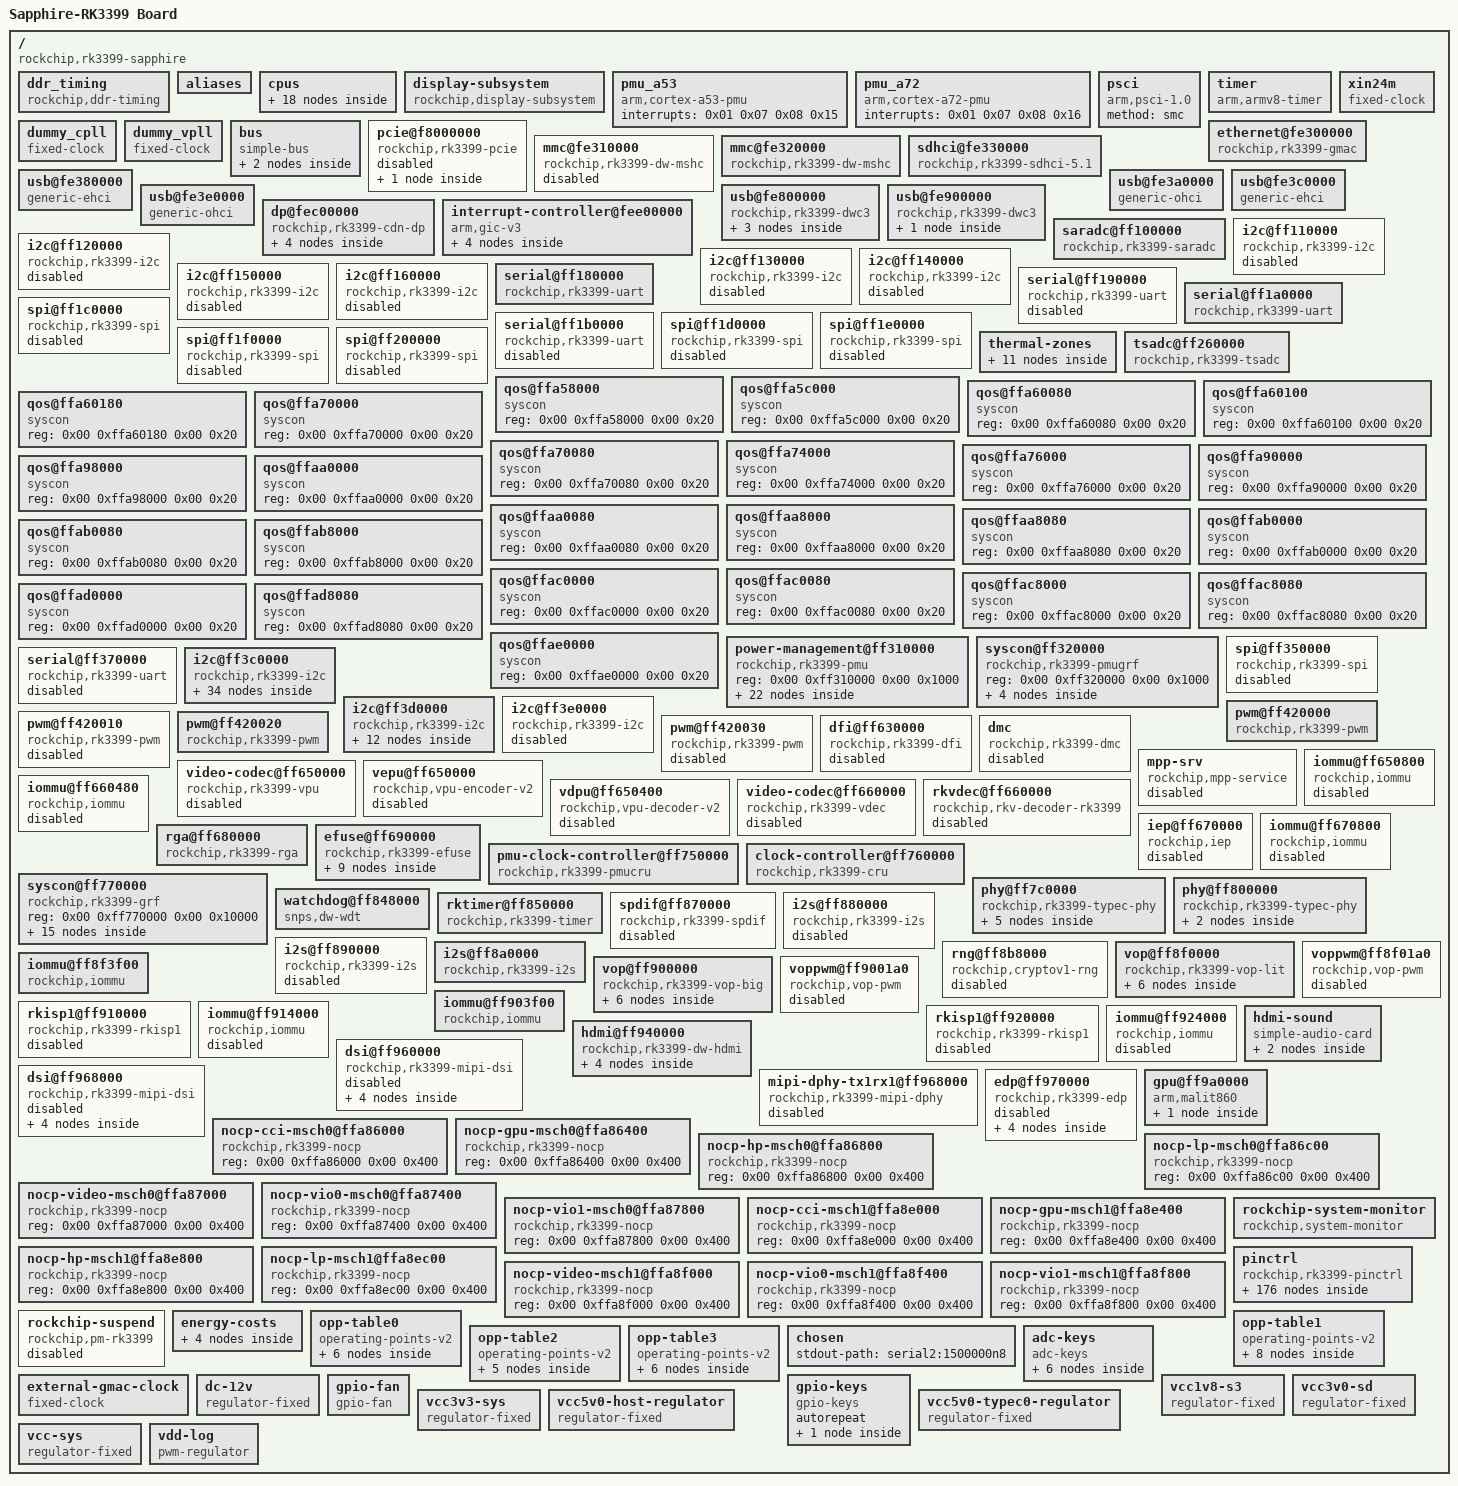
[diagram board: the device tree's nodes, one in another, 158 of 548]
/dts-v1/;

/ {
	compatible = "rockchip,rk3399-sapphire\0rockchip,rk3399";
	interrupt-parent = <0x01>;
	#address-cells = <0x02>;
	#size-cells = <0x02>;
	model = "Sapphire-RK3399 Board";

	ddr_timing {
		compatible = "rockchip,ddr-timing";
		ddr3_speed_bin = <0x15>;
		pd_idle = <0x00>;
		sr_idle = <0x00>;
		sr_mc_gate_idle = <0x00>;
		srpd_lite_idle = <0x00>;
		standby_idle = <0x00>;
		auto_lp_dis_freq = <0x29a>;
		ddr3_dll_dis_freq = <0x12c>;
		phy_dll_dis_freq = <0x104>;
		ddr3_odt_dis_freq = <0x29a>;
		ddr3_drv = <0x28>;
		ddr3_odt = <0x78>;
		phy_ddr3_ca_drv = <0x28>;
		phy_ddr3_dq_drv = <0x28>;
		phy_ddr3_odt = <0xf0>;
		lpddr3_odt_dis_freq = <0x29a>;
		lpddr3_drv = <0x22>;
		lpddr3_odt = <0xf0>;
		phy_lpddr3_ca_drv = <0x22>;
		phy_lpddr3_dq_drv = <0x22>;
		phy_lpddr3_odt = <0xf0>;
		lpddr4_odt_dis_freq = <0x320>;
		lpddr4_drv = <0xf0>;
		lpddr4_dq_odt = <0x28>;
		lpddr4_ca_odt = <0x00>;
		phy_lpddr4_ca_drv = <0x28>;
		phy_lpddr4_ck_cs_drv = <0x28>;
		phy_lpddr4_dq_drv = <0x3c>;
		phy_lpddr4_odt = <0x28>;
		phandle = <0x8f>;
	};

	aliases {
		dsi0 = "/dsi@ff960000";
		dsi1 = "/dsi@ff968000";
		ethernet0 = "/ethernet@fe300000";
		gpio0 = "/pinctrl/gpio0@ff720000";
		gpio1 = "/pinctrl/gpio1@ff730000";
		gpio2 = "/pinctrl/gpio2@ff780000";
		gpio3 = "/pinctrl/gpio3@ff788000";
		gpio4 = "/pinctrl/gpio4@ff790000";
		i2c0 = "/i2c@ff3c0000";
		i2c1 = "/i2c@ff110000";
		i2c2 = "/i2c@ff120000";
		i2c3 = "/i2c@ff130000";
		i2c4 = "/i2c@ff3d0000";
		i2c5 = "/i2c@ff140000";
		i2c6 = "/i2c@ff150000";
		i2c7 = "/i2c@ff160000";
		i2c8 = "/i2c@ff3e0000";
		mmc0 = "/mmc@fe310000";
		mmc1 = "/mmc@fe320000";
		mmc2 = "/sdhci@fe330000";
		serial0 = "/serial@ff180000";
		serial1 = "/serial@ff190000";
		serial2 = "/serial@ff1a0000";
		serial3 = "/serial@ff1b0000";
		serial4 = "/serial@ff370000";
	};

	cpus {
		#address-cells = <0x02>;
		#size-cells = <0x00>;

		cpu-map {

			cluster0 {

				core0 {
					cpu = <0x02>;
				};

				core1 {
					cpu = <0x03>;
				};

				core2 {
					cpu = <0x04>;
				};

				core3 {
					cpu = <0x05>;
				};
			};

			cluster1 {

				core0 {
					cpu = <0x06>;
				};

				core1 {
					cpu = <0x07>;
				};
			};
		};

		cpu@0 {
			device_type = "cpu";
			compatible = "arm,cortex-a53";
			reg = <0x00 0x00>;
			enable-method = "psci";
			capacity-dmips-mhz = <0x1e5>;
			clocks = <0x08 0x08>;
			#cooling-cells = <0x02>;
			dynamic-power-coefficient = <0x64>;
			cpu-idle-states = <0x09 0x0a>;
			operating-points-v2 = <0x0b>;
			sched-energy-costs = <0x0c 0x0d>;
			cpu-supply = <0x0e>;
			phandle = <0x02>;
		};

		cpu@1 {
			device_type = "cpu";
			compatible = "arm,cortex-a53";
			reg = <0x00 0x01>;
			enable-method = "psci";
			capacity-dmips-mhz = <0x1e5>;
			clocks = <0x08 0x08>;
			#cooling-cells = <0x02>;
			dynamic-power-coefficient = <0x64>;
			cpu-idle-states = <0x09 0x0a>;
			operating-points-v2 = <0x0b>;
			sched-energy-costs = <0x0c 0x0d>;
			cpu-supply = <0x0e>;
			phandle = <0x03>;
		};

		cpu@2 {
			device_type = "cpu";
			compatible = "arm,cortex-a53";
			reg = <0x00 0x02>;
			enable-method = "psci";
			capacity-dmips-mhz = <0x1e5>;
			clocks = <0x08 0x08>;
			#cooling-cells = <0x02>;
			dynamic-power-coefficient = <0x64>;
			cpu-idle-states = <0x09 0x0a>;
			operating-points-v2 = <0x0b>;
			sched-energy-costs = <0x0c 0x0d>;
			cpu-supply = <0x0e>;
			phandle = <0x04>;
		};

		cpu@3 {
			device_type = "cpu";
			compatible = "arm,cortex-a53";
			reg = <0x00 0x03>;
			enable-method = "psci";
			capacity-dmips-mhz = <0x1e5>;
			clocks = <0x08 0x08>;
			#cooling-cells = <0x02>;
			dynamic-power-coefficient = <0x64>;
			cpu-idle-states = <0x09 0x0a>;
			operating-points-v2 = <0x0b>;
			sched-energy-costs = <0x0c 0x0d>;
			cpu-supply = <0x0e>;
			phandle = <0x05>;
		};

		cpu@100 {
			device_type = "cpu";
			compatible = "arm,cortex-a72";
			reg = <0x00 0x100>;
			enable-method = "psci";
			capacity-dmips-mhz = <0x400>;
			clocks = <0x08 0x09>;
			#cooling-cells = <0x02>;
			dynamic-power-coefficient = <0x1b4>;
			cpu-idle-states = <0x09 0x0a>;
			operating-points-v2 = <0x0f>;
			sched-energy-costs = <0x10 0x11>;
			cpu-supply = <0x12>;
			phandle = <0x06>;
		};

		cpu@101 {
			device_type = "cpu";
			compatible = "arm,cortex-a72";
			reg = <0x00 0x101>;
			enable-method = "psci";
			capacity-dmips-mhz = <0x400>;
			clocks = <0x08 0x09>;
			#cooling-cells = <0x02>;
			dynamic-power-coefficient = <0x1b4>;
			cpu-idle-states = <0x09 0x0a>;
			operating-points-v2 = <0x0f>;
			sched-energy-costs = <0x10 0x11>;
			cpu-supply = <0x12>;
			phandle = <0x07>;
		};

		idle-states {
			entry-method = "psci";

			cpu-sleep {
				compatible = "arm,idle-state";
				local-timer-stop;
				arm,psci-suspend-param = <0x10000>;
				entry-latency-us = <0x78>;
				exit-latency-us = <0xfa>;
				min-residency-us = <0x384>;
				phandle = <0x09>;
			};

			cluster-sleep {
				compatible = "arm,idle-state";
				local-timer-stop;
				arm,psci-suspend-param = <0x1010000>;
				entry-latency-us = <0x190>;
				exit-latency-us = <0x1f4>;
				min-residency-us = <0x7d0>;
				phandle = <0x0a>;
			};
		};
	};

	display-subsystem {
		compatible = "rockchip,display-subsystem";
		ports = <0x13 0x14>;
		clocks = <0x08 0x07 0x08 0x04>;
		clock-names = "hdmi-tmds-pll\0default-vop-pll";
	};

	pmu_a53 {
		compatible = "arm,cortex-a53-pmu";
		interrupts = <0x01 0x07 0x08 0x15>;
	};

	pmu_a72 {
		compatible = "arm,cortex-a72-pmu";
		interrupts = <0x01 0x07 0x08 0x16>;
	};

	psci {
		compatible = "arm,psci-1.0";
		method = "smc";
	};

	timer {
		compatible = "arm,armv8-timer";
		interrupts = <0x01 0x0d 0x08 0x00 0x01 0x0e 0x08 0x00 0x01 0x0b 0x08 0x00 0x01 0x0a 0x08 0x00>;
		arm,no-tick-in-suspend;
	};

	xin24m {
		compatible = "fixed-clock";
		clock-frequency = <0x16e3600>;
		clock-output-names = "xin24m";
		#clock-cells = <0x00>;
	};

	dummy_cpll {
		compatible = "fixed-clock";
		clock-frequency = <0x00>;
		clock-output-names = "dummy_cpll";
		#clock-cells = <0x00>;
	};

	dummy_vpll {
		compatible = "fixed-clock";
		clock-frequency = <0x00>;
		clock-output-names = "dummy_vpll";
		#clock-cells = <0x00>;
	};

	bus {
		compatible = "simple-bus";
		#address-cells = <0x02>;
		#size-cells = <0x02>;
		ranges;

		dma-controller@ff6d0000 {
			compatible = "arm,pl330\0arm,primecell";
			reg = <0x00 0xff6d0000 0x00 0x4000>;
			interrupts = <0x00 0x05 0x04 0x00 0x00 0x06 0x04 0x00>;
			#dma-cells = <0x01>;
			arm,pl330-periph-burst;
			clocks = <0x08 0xd3>;
			clock-names = "apb_pclk";
			phandle = <0x50>;
		};

		dma-controller@ff6e0000 {
			compatible = "arm,pl330\0arm,primecell";
			reg = <0x00 0xff6e0000 0x00 0x4000>;
			interrupts = <0x00 0x07 0x04 0x00 0x00 0x08 0x04 0x00>;
			#dma-cells = <0x01>;
			arm,pl330-periph-burst;
			clocks = <0x08 0xd4>;
			clock-names = "apb_pclk";
			phandle = <0x3f>;
		};
	};

	pcie@f8000000 {
		compatible = "rockchip,rk3399-pcie";
		reg = <0x00 0xf8000000 0x00 0x2000000 0x00 0xfd000000 0x00 0x1000000>;
		reg-names = "axi-base\0apb-base";
		device_type = "pci";
		#address-cells = <0x03>;
		#size-cells = <0x02>;
		#interrupt-cells = <0x01>;
		aspm-no-l0s;
		bus-range = <0x00 0x1f>;
		clocks = <0x08 0xc5 0x08 0xc4 0x08 0x147 0x08 0xa0>;
		clock-names = "aclk\0aclk-perf\0hclk\0pm";
		interrupts = <0x00 0x31 0x04 0x00 0x00 0x32 0x04 0x00 0x00 0x33 0x04 0x00>;
		interrupt-names = "sys\0legacy\0client";
		interrupt-map-mask = <0x00 0x00 0x00 0x07>;
		interrupt-map = <0x00 0x00 0x00 0x01 0x17 0x00 0x00 0x00 0x00 0x02 0x17 0x01 0x00 0x00 0x00 0x03 0x17 0x02 0x00 0x00 0x00 0x04 0x17 0x03>;
		max-link-speed = <0x01>;
		msi-map = <0x00 0x18 0x00 0x1000>;
		phys = <0x19 0x00 0x19 0x01 0x19 0x02 0x19 0x03>;
		phy-names = "pcie-phy-0\0pcie-phy-1\0pcie-phy-2\0pcie-phy-3";
		power-domains = <0x1a 0x0e>;
		ranges = <0x83000000 0x00 0xfa000000 0x00 0xfa000000 0x00 0x1e00000 0x81000000 0x00 0xfbe00000 0x00 0xfbe00000 0x00 0x100000>;
		resets = <0x08 0x82 0x08 0x83 0x08 0x84 0x08 0x85 0x08 0x86 0x08 0x81 0x08 0x80>;
		reset-names = "core\0mgmt\0mgmt-sticky\0pipe\0pm\0pclk\0aclk";
		status = "disabled";

		interrupt-controller {
			interrupt-controller;
			#address-cells = <0x00>;
			#interrupt-cells = <0x01>;
			phandle = <0x17>;
		};
	};

	ethernet@fe300000 {
		compatible = "rockchip,rk3399-gmac";
		reg = <0x00 0xfe300000 0x00 0x10000>;
		interrupts = <0x00 0x0c 0x04 0x00>;
		interrupt-names = "macirq";
		clocks = <0x08 0x69 0x08 0x67 0x08 0x68 0x08 0x66 0x08 0x6a 0x08 0xd5 0x08 0x166>;
		clock-names = "stmmaceth\0mac_clk_rx\0mac_clk_tx\0clk_mac_ref\0clk_mac_refout\0aclk_mac\0pclk_mac";
		power-domains = <0x1a 0x16>;
		resets = <0x08 0x89>;
		reset-names = "stmmaceth";
		rockchip,grf = <0x1b>;
		snps,txpbl = <0x04>;
		status = "okay";
		assigned-clocks = <0x08 0xa6>;
		assigned-clock-parents = <0x1c>;
		clock_in_out = "input";
		phy-supply = <0x1d>;
		phy-mode = "rgmii";
		pinctrl-names = "default";
		pinctrl-0 = <0x1e>;
		snps,reset-gpio = <0x1f 0x0f 0x01>;
		snps,reset-active-low;
		snps,reset-delays-us = <0x00 0x2710 0xc350>;
		tx_delay = <0x28>;
		rx_delay = <0x11>;
	};

	mmc@fe310000 {
		compatible = "rockchip,rk3399-dw-mshc\0rockchip,rk3288-dw-mshc";
		reg = <0x00 0xfe310000 0x00 0x4000>;
		interrupts = <0x00 0x40 0x04 0x00>;
		max-frequency = <0x8f0d180>;
		clocks = <0x08 0x1ee 0x08 0x4d 0x08 0x9c 0x08 0x9d>;
		clock-names = "biu\0ciu\0ciu-drive\0ciu-sample";
		fifo-depth = <0x100>;
		power-domains = <0x1a 0x1c>;
		resets = <0x08 0x79>;
		reset-names = "reset";
		status = "disabled";
	};

	mmc@fe320000 {
		compatible = "rockchip,rk3399-dw-mshc\0rockchip,rk3288-dw-mshc";
		reg = <0x00 0xfe320000 0x00 0x4000>;
		interrupts = <0x00 0x41 0x04 0x00>;
		max-frequency = <0x8f0d180>;
		assigned-clocks = <0x08 0x1cd>;
		assigned-clock-rates = <0xbebc200>;
		clocks = <0x08 0x1ce 0x08 0x4c 0x08 0x9a 0x08 0x9b>;
		clock-names = "biu\0ciu\0ciu-drive\0ciu-sample";
		fifo-depth = <0x100>;
		power-domains = <0x1a 0x1b>;
		resets = <0x08 0x7a>;
		reset-names = "reset";
		status = "okay";
		broken-cd;
		bus-width = <0x04>;
		cap-mmc-highspeed;
		cap-sd-highspeed;
		clock-frequency = <0x8f0d180>;
		disable-wp;
		pinctrl-names = "default";
		pinctrl-0 = <0x20 0x21 0x22 0x23>;
		vmmc-supply = <0x24>;
		vqmmc-supply = <0x25>;
	};

	sdhci@fe330000 {
		compatible = "rockchip,rk3399-sdhci-5.1\0arasan,sdhci-5.1";
		reg = <0x00 0xfe330000 0x00 0x10000>;
		interrupts = <0x00 0x0b 0x04 0x00>;
		arasan,soc-ctl-syscon = <0x1b>;
		assigned-clocks = <0x08 0x4e>;
		assigned-clock-rates = <0xbebc200>;
		clocks = <0x08 0x4e 0x08 0xf0>;
		clock-names = "clk_xin\0clk_ahb";
		clock-output-names = "emmc_cardclock";
		#clock-cells = <0x00>;
		phys = <0x26>;
		phy-names = "phy_arasan";
		power-domains = <0x1a 0x17>;
		disable-cqe-dcmd;
		disable-cqe;
		status = "okay";
		bus-width = <0x08>;
		mmc-hs400-1_8v;
		mmc-hs400-enhanced-strobe;
		non-removable;
		phandle = <0x97>;
	};

	usb@fe380000 {
		compatible = "generic-ehci";
		reg = <0x00 0xfe380000 0x00 0x20000>;
		interrupts = <0x00 0x1a 0x04 0x00>;
		clocks = <0x08 0x1c8 0x08 0x1c9 0x27>;
		phys = <0x28>;
		phy-names = "usb";
		status = "okay";
	};

	usb@fe3a0000 {
		compatible = "generic-ohci";
		reg = <0x00 0xfe3a0000 0x00 0x20000>;
		interrupts = <0x00 0x1c 0x04 0x00>;
		clocks = <0x08 0x1c8 0x08 0x1c9 0x27>;
		phys = <0x28>;
		phy-names = "usb";
		status = "okay";
	};

	usb@fe3c0000 {
		compatible = "generic-ehci";
		reg = <0x00 0xfe3c0000 0x00 0x20000>;
		interrupts = <0x00 0x1e 0x04 0x00>;
		clocks = <0x08 0x1ca 0x08 0x1cb 0x29>;
		phys = <0x2a>;
		phy-names = "usb";
		status = "okay";
	};

	usb@fe3e0000 {
		compatible = "generic-ohci";
		reg = <0x00 0xfe3e0000 0x00 0x20000>;
		interrupts = <0x00 0x20 0x04 0x00>;
		clocks = <0x08 0x1ca 0x08 0x1cb 0x29>;
		phys = <0x2a>;
		phy-names = "usb";
		status = "okay";
	};

	usb@fe800000 {
		compatible = "rockchip,rk3399-dwc3";
		#address-cells = <0x02>;
		#size-cells = <0x02>;
		ranges;
		clocks = <0x08 0x81 0x08 0x83 0x08 0xf6 0x08 0xf8 0x08 0xf4 0x08 0xf9>;
		clock-names = "ref_clk\0suspend_clk\0bus_clk\0aclk_usb3_rksoc_axi_perf\0aclk_usb3\0grf_clk";
		status = "okay";

		usb@fe800000 {
			compatible = "snps,dwc3";
			reg = <0x00 0xfe800000 0x00 0x100000>;
			interrupts = <0x00 0x69 0x04 0x00>;
			clocks = <0x08 0x81 0x08 0xf6 0x08 0x83>;
			clock-names = "ref\0bus_early\0suspend";
			resets = <0x08 0x125>;
			reset-names = "usb3-otg";
			dr_mode = "otg";
			phys = <0x2b 0x2c>;
			phy-names = "usb2-phy\0usb3-phy";
			phy_type = "utmi_wide";
			snps,dis_enblslpm_quirk;
			snps,dis-u1-entry-quirk;
			snps,dis-u2-entry-quirk;
			snps,dis-u2-freeclk-exists-quirk;
			snps,dis_u2_susphy_quirk;
			snps,dis-del-phy-power-chg-quirk;
			snps,dis-tx-ipgap-linecheck-quirk;
			snps,parkmode-disable-ss-quirk;
			power-domains = <0x1a 0x18>;
			status = "okay";
			usb-role-switch;

			port {
				#address-cells = <0x01>;
				#size-cells = <0x00>;

				endpoint@0 {
					reg = <0x00>;
					remote-endpoint = <0x2d>;
					phandle = <0x84>;
				};
			};
		};
	};

	usb@fe900000 {
		compatible = "rockchip,rk3399-dwc3";
		#address-cells = <0x02>;
		#size-cells = <0x02>;
		ranges;
		clocks = <0x08 0x82 0x08 0x84 0x08 0xf7 0x08 0xf8 0x08 0xf4 0x08 0xf9>;
		clock-names = "ref_clk\0suspend_clk\0bus_clk\0aclk_usb3_rksoc_axi_perf\0aclk_usb3\0grf_clk";
		status = "okay";

		usb@fe900000 {
			compatible = "snps,dwc3";
			reg = <0x00 0xfe900000 0x00 0x100000>;
			interrupts = <0x00 0x6e 0x04 0x00>;
			clocks = <0x08 0x82 0x08 0xf7 0x08 0x84>;
			clock-names = "ref\0bus_early\0suspend";
			resets = <0x08 0x126>;
			reset-names = "usb3-otg";
			dr_mode = "host";
			phys = <0x2e 0x2f>;
			phy-names = "usb2-phy\0usb3-phy";
			phy_type = "utmi_wide";
			snps,dis_enblslpm_quirk;
			snps,dis-u2-freeclk-exists-quirk;
			snps,dis_u2_susphy_quirk;
			snps,dis-del-phy-power-chg-quirk;
			snps,dis-tx-ipgap-linecheck-quirk;
			snps,parkmode-disable-ss-quirk;
			power-domains = <0x1a 0x18>;
			status = "okay";
		};
	};

	dp@fec00000 {
		compatible = "rockchip,rk3399-cdn-dp";
		reg = <0x00 0xfec00000 0x00 0x100000>;
		interrupts = <0x00 0x09 0x04 0x00>;
		assigned-clocks = <0x08 0x72 0x08 0xa1>;
		assigned-clock-rates = <0x5f5e100 0xbebc200>;
		clocks = <0x08 0x72 0x08 0x175 0x08 0xa1 0x08 0x16f>;
		clock-names = "core-clk\0pclk\0spdif\0grf";
		phys = <0x30>;
		power-domains = <0x1a 0x15>;
		resets = <0x08 0x103 0x08 0x148 0x08 0x14a 0x08 0xfd>;
		reset-names = "spdif\0dptx\0apb\0core";
		rockchip,grf = <0x1b>;
		#sound-dai-cells = <0x01>;
		status = "okay";
		phandle = <0x85>;

		ports {

			port {
				#address-cells = <0x01>;
				#size-cells = <0x00>;

				endpoint@0 {
					reg = <0x00>;
					remote-endpoint = <0x31>;
					phandle = <0xa9>;
				};

				endpoint@1 {
					reg = <0x01>;
					remote-endpoint = <0x32>;
					phandle = <0xa2>;
				};
			};
		};
	};

	interrupt-controller@fee00000 {
		compatible = "arm,gic-v3";
		#interrupt-cells = <0x04>;
		#address-cells = <0x02>;
		#size-cells = <0x02>;
		ranges;
		interrupt-controller;
		reg = <0x00 0xfee00000 0x00 0x10000 0x00 0xfef00000 0x00 0xc0000 0x00 0xfff00000 0x00 0x10000 0x00 0xfff10000 0x00 0x10000 0x00 0xfff20000 0x00 0x10000>;
		interrupts = <0x01 0x09 0x04 0x00>;
		phandle = <0x01>;

		interrupt-controller@fee20000 {
			compatible = "arm,gic-v3-its";
			msi-controller;
			#msi-cells = <0x01>;
			reg = <0x00 0xfee20000 0x00 0x20000>;
			phandle = <0x18>;
		};

		ppi-partitions {

			interrupt-partition-0 {
				affinity = <0x02 0x03 0x04 0x05>;
				phandle = <0x15>;
			};

			interrupt-partition-1 {
				affinity = <0x06 0x07>;
				phandle = <0x16>;
			};
		};
	};

	saradc@ff100000 {
		compatible = "rockchip,rk3399-saradc";
		reg = <0x00 0xff100000 0x00 0x100>;
		interrupts = <0x00 0x3e 0x04 0x00>;
		#io-channel-cells = <0x01>;
		clocks = <0x08 0x50 0x08 0x165>;
		clock-names = "saradc\0apb_pclk";
		resets = <0x08 0xd4>;
		reset-names = "saradc-apb";
		status = "okay";
		vref-supply = <0x33>;
		phandle = <0xc6>;
	};

	i2c@ff110000 {
		compatible = "rockchip,rk3399-i2c";
		reg = <0x00 0xff110000 0x00 0x1000>;
		assigned-clocks = <0x08 0x41>;
		assigned-clock-rates = <0xbebc200>;
		clocks = <0x08 0x41 0x08 0x155>;
		clock-names = "i2c\0pclk";
		interrupts = <0x00 0x3b 0x04 0x00>;
		pinctrl-names = "default";
		pinctrl-0 = <0x34>;
		#address-cells = <0x01>;
		#size-cells = <0x00>;
		status = "disabled";
	};

	i2c@ff120000 {
		compatible = "rockchip,rk3399-i2c";
		reg = <0x00 0xff120000 0x00 0x1000>;
		assigned-clocks = <0x08 0x42>;
		assigned-clock-rates = <0xbebc200>;
		clocks = <0x08 0x42 0x08 0x156>;
		clock-names = "i2c\0pclk";
		interrupts = <0x00 0x23 0x04 0x00>;
		pinctrl-names = "default";
		pinctrl-0 = <0x35>;
		#address-cells = <0x01>;
		#size-cells = <0x00>;
		status = "disabled";
	};

	i2c@ff130000 {
		compatible = "rockchip,rk3399-i2c";
		reg = <0x00 0xff130000 0x00 0x1000>;
		assigned-clocks = <0x08 0x43>;
		assigned-clock-rates = <0xbebc200>;
		clocks = <0x08 0x43 0x08 0x157>;
		clock-names = "i2c\0pclk";
		interrupts = <0x00 0x22 0x04 0x00>;
		pinctrl-names = "default";
		pinctrl-0 = <0x36>;
		#address-cells = <0x01>;
		#size-cells = <0x00>;
		status = "disabled";
	};

	i2c@ff140000 {
		compatible = "rockchip,rk3399-i2c";
		reg = <0x00 0xff140000 0x00 0x1000>;
		assigned-clocks = <0x08 0x44>;
		assigned-clock-rates = <0xbebc200>;
		clocks = <0x08 0x44 0x08 0x158>;
		clock-names = "i2c\0pclk";
		interrupts = <0x00 0x26 0x04 0x00>;
		pinctrl-names = "default";
		pinctrl-0 = <0x37>;
		#address-cells = <0x01>;
		#size-cells = <0x00>;
		status = "disabled";
	};

	i2c@ff150000 {
		compatible = "rockchip,rk3399-i2c";
		reg = <0x00 0xff150000 0x00 0x1000>;
		assigned-clocks = <0x08 0x45>;
		assigned-clock-rates = <0xbebc200>;
		clocks = <0x08 0x45 0x08 0x159>;
		clock-names = "i2c\0pclk";
		interrupts = <0x00 0x25 0x04 0x00>;
		pinctrl-names = "default";
		pinctrl-0 = <0x38>;
		#address-cells = <0x01>;
		#size-cells = <0x00>;
		status = "disabled";
	};

	i2c@ff160000 {
		compatible = "rockchip,rk3399-i2c";
		reg = <0x00 0xff160000 0x00 0x1000>;
		assigned-clocks = <0x08 0x46>;
		assigned-clock-rates = <0xbebc200>;
		clocks = <0x08 0x46 0x08 0x15a>;
		clock-names = "i2c\0pclk";
		interrupts = <0x00 0x24 0x04 0x00>;
		pinctrl-names = "default";
		pinctrl-0 = <0x39>;
		#address-cells = <0x01>;
		#size-cells = <0x00>;
		status = "disabled";
	};

	serial@ff180000 {
		compatible = "rockchip,rk3399-uart\0snps,dw-apb-uart";
		reg = <0x00 0xff180000 0x00 0x100>;
		clocks = <0x08 0x51 0x08 0x160>;
		clock-names = "baudclk\0apb_pclk";
		interrupts = <0x00 0x63 0x04 0x00>;
		reg-shift = <0x02>;
		reg-io-width = <0x04>;
		pinctrl-names = "default";
		pinctrl-0 = <0x3a 0x3b>;
		status = "okay";
	};

	serial@ff190000 {
		compatible = "rockchip,rk3399-uart\0snps,dw-apb-uart";
		reg = <0x00 0xff190000 0x00 0x100>;
		clocks = <0x08 0x52 0x08 0x161>;
		clock-names = "baudclk\0apb_pclk";
		interrupts = <0x00 0x62 0x04 0x00>;
		reg-shift = <0x02>;
		reg-io-width = <0x04>;
		pinctrl-names = "default";
		pinctrl-0 = <0x3c>;
		status = "disabled";
	};

	serial@ff1a0000 {
		compatible = "rockchip,rk3399-uart\0snps,dw-apb-uart";
		reg = <0x00 0xff1a0000 0x00 0x100>;
		clocks = <0x08 0x53 0x08 0x162>;
		clock-names = "baudclk\0apb_pclk";
		interrupts = <0x00 0x64 0x04 0x00>;
		reg-shift = <0x02>;
		reg-io-width = <0x04>;
		pinctrl-names = "default";
		pinctrl-0 = <0x3d>;
		status = "okay";
	};

	serial@ff1b0000 {
		compatible = "rockchip,rk3399-uart\0snps,dw-apb-uart";
		reg = <0x00 0xff1b0000 0x00 0x100>;
		clocks = <0x08 0x54 0x08 0x163>;
		clock-names = "baudclk\0apb_pclk";
		interrupts = <0x00 0x65 0x04 0x00>;
		reg-shift = <0x02>;
		reg-io-width = <0x04>;
		pinctrl-names = "default";
		pinctrl-0 = <0x3e>;
		status = "disabled";
	};

	spi@ff1c0000 {
		compatible = "rockchip,rk3399-spi\0rockchip,rk3066-spi";
		reg = <0x00 0xff1c0000 0x00 0x1000>;
		clocks = <0x08 0x47 0x08 0x15b>;
		clock-names = "spiclk\0apb_pclk";
		interrupts = <0x00 0x44 0x04 0x00>;
		dmas = <0x3f 0x0a 0x3f 0x0b>;
		dma-names = "tx\0rx";
		pinctrl-names = "default";
		pinctrl-0 = <0x40 0x41 0x42 0x43>;
		#address-cells = <0x01>;
		#size-cells = <0x00>;
		status = "disabled";
	};

	spi@ff1d0000 {
		compatible = "rockchip,rk3399-spi\0rockchip,rk3066-spi";
		reg = <0x00 0xff1d0000 0x00 0x1000>;
		clocks = <0x08 0x48 0x08 0x15c>;
		clock-names = "spiclk\0apb_pclk";
		interrupts = <0x00 0x35 0x04 0x00>;
		dmas = <0x3f 0x0c 0x3f 0x0d>;
		dma-names = "tx\0rx";
		pinctrl-names = "default";
		pinctrl-0 = <0x44 0x45 0x46 0x47>;
		#address-cells = <0x01>;
		#size-cells = <0x00>;
		status = "disabled";
	};

	spi@ff1e0000 {
		compatible = "rockchip,rk3399-spi\0rockchip,rk3066-spi";
		reg = <0x00 0xff1e0000 0x00 0x1000>;
		clocks = <0x08 0x49 0x08 0x15d>;
		clock-names = "spiclk\0apb_pclk";
		interrupts = <0x00 0x34 0x04 0x00>;
		dmas = <0x3f 0x0e 0x3f 0x0f>;
		dma-names = "tx\0rx";
		pinctrl-names = "default";
		pinctrl-0 = <0x48 0x49 0x4a 0x4b>;
		#address-cells = <0x01>;
		#size-cells = <0x00>;
		status = "disabled";
	};

	spi@ff1f0000 {
		compatible = "rockchip,rk3399-spi\0rockchip,rk3066-spi";
		reg = <0x00 0xff1f0000 0x00 0x1000>;
		clocks = <0x08 0x4a 0x08 0x15e>;
		clock-names = "spiclk\0apb_pclk";
		interrupts = <0x00 0x43 0x04 0x00>;
		dmas = <0x3f 0x12 0x3f 0x13>;
		dma-names = "tx\0rx";
		pinctrl-names = "default";
		pinctrl-0 = <0x4c 0x4d 0x4e 0x4f>;
		#address-cells = <0x01>;
		#size-cells = <0x00>;
		status = "disabled";
	};

	spi@ff200000 {
		compatible = "rockchip,rk3399-spi\0rockchip,rk3066-spi";
		reg = <0x00 0xff200000 0x00 0x1000>;
		clocks = <0x08 0x4b 0x08 0x15f>;
		clock-names = "spiclk\0apb_pclk";
		interrupts = <0x00 0x84 0x04 0x00>;
		dmas = <0x50 0x08 0x50 0x09>;
		dma-names = "tx\0rx";
		pinctrl-names = "default";
		pinctrl-0 = <0x51 0x52 0x53 0x54>;
		power-domains = <0x1a 0x1c>;
		#address-cells = <0x01>;
		#size-cells = <0x00>;
		status = "disabled";
	};

	thermal-zones {

		cpu-thermal {
			polling-delay-passive = <0x14>;
			polling-delay = <0x3e8>;
			sustainable-power = <0x3e8>;
			thermal-sensors = <0x55 0x00>;

			trips {

				cpu_alert0 {
					temperature = <0x11170>;
					hysteresis = <0x7d0>;
					type = "passive";
				};

				cpu_alert1 {
					temperature = <0x14c08>;
					hysteresis = <0x7d0>;
					type = "passive";
					phandle = <0x56>;
				};

				cpu_crit {
					temperature = <0x1c138>;
					hysteresis = <0x7d0>;
					type = "critical";
				};

				cpu_hot {
					hysteresis = <0x2710>;
					temperature = <0xd6d8>;
					type = "active";
					phandle = <0x57>;
				};
			};

			cooling-maps {

				map0 {
					trip = <0x56>;
					cooling-device = <0x02 0xffffffff 0xffffffff>;
					contribution = <0x1000>;
				};

				map1 {
					trip = <0x56>;
					cooling-device = <0x06 0xffffffff 0xffffffff>;
					contribution = <0x400>;
				};

				map2 {
					trip = <0x57>;
					cooling-device = <0x58 0xffffffff 0xffffffff>;
					contribution = <0x1000>;
				};
			};
		};

		gpu-thermal {
			polling-delay-passive = <0x64>;
			polling-delay = <0x3e8>;
			thermal-sensors = <0x55 0x01>;
		};
	};

	tsadc@ff260000 {
		compatible = "rockchip,rk3399-tsadc";
		reg = <0x00 0xff260000 0x00 0x100>;
		interrupts = <0x00 0x61 0x04 0x00>;
		assigned-clocks = <0x08 0x4f>;
		assigned-clock-rates = <0xb71b0>;
		clocks = <0x08 0x4f 0x08 0x164>;
		clock-names = "tsadc\0apb_pclk";
		resets = <0x08 0xe8>;
		reset-names = "tsadc-apb";
		rockchip,grf = <0x1b>;
		rockchip,hw-tshut-temp = <0x17318>;
		pinctrl-names = "gpio\0otpout";
		pinctrl-0 = <0x59>;
		pinctrl-1 = <0x5a>;
		#thermal-sensor-cells = <0x01>;
		status = "okay";
		rockchip,hw-tshut-mode = <0x01>;
		rockchip,hw-tshut-polarity = <0x01>;
		phandle = <0x55>;
	};

	qos@ffa58000 {
		compatible = "syscon";
		reg = <0x00 0xffa58000 0x00 0x20>;
		phandle = <0x62>;
	};

	qos@ffa5c000 {
		compatible = "syscon";
		reg = <0x00 0xffa5c000 0x00 0x20>;
		phandle = <0x63>;
	};

	qos@ffa60080 {
		compatible = "syscon";
		reg = <0x00 0xffa60080 0x00 0x20>;
		phandle = <0x65>;
	};

	qos@ffa60100 {
		compatible = "syscon";
		reg = <0x00 0xffa60100 0x00 0x20>;
		phandle = <0x66>;
	};

	qos@ffa60180 {
		compatible = "syscon";
		reg = <0x00 0xffa60180 0x00 0x20>;
		phandle = <0x67>;
	};

	qos@ffa70000 {
		compatible = "syscon";
		reg = <0x00 0xffa70000 0x00 0x20>;
		phandle = <0x6a>;
	};

	qos@ffa70080 {
		compatible = "syscon";
		reg = <0x00 0xffa70080 0x00 0x20>;
		phandle = <0x6b>;
	};

	qos@ffa74000 {
		compatible = "syscon";
		reg = <0x00 0xffa74000 0x00 0x20>;
		phandle = <0x68>;
	};

	qos@ffa76000 {
		compatible = "syscon";
		reg = <0x00 0xffa76000 0x00 0x20>;
		phandle = <0x69>;
	};

	qos@ffa90000 {
		compatible = "syscon";
		reg = <0x00 0xffa90000 0x00 0x20>;
		phandle = <0x6c>;
	};

	qos@ffa98000 {
		compatible = "syscon";
		reg = <0x00 0xffa98000 0x00 0x20>;
		phandle = <0x5b>;
	};

	qos@ffaa0000 {
		compatible = "syscon";
		reg = <0x00 0xffaa0000 0x00 0x20>;
		phandle = <0x6d>;
	};

	qos@ffaa0080 {
		compatible = "syscon";
		reg = <0x00 0xffaa0080 0x00 0x20>;
		phandle = <0x6e>;
	};

	qos@ffaa8000 {
		compatible = "syscon";
		reg = <0x00 0xffaa8000 0x00 0x20>;
		phandle = <0x6f>;
	};

	qos@ffaa8080 {
		compatible = "syscon";
		reg = <0x00 0xffaa8080 0x00 0x20>;
		phandle = <0x70>;
	};

	qos@ffab0000 {
		compatible = "syscon";
		reg = <0x00 0xffab0000 0x00 0x20>;
		phandle = <0x5c>;
	};

	qos@ffab0080 {
		compatible = "syscon";
		reg = <0x00 0xffab0080 0x00 0x20>;
		phandle = <0x5d>;
	};

	qos@ffab8000 {
		compatible = "syscon";
		reg = <0x00 0xffab8000 0x00 0x20>;
		phandle = <0x5e>;
	};

	qos@ffac0000 {
		compatible = "syscon";
		reg = <0x00 0xffac0000 0x00 0x20>;
		phandle = <0x5f>;
	};

	qos@ffac0080 {
		compatible = "syscon";
		reg = <0x00 0xffac0080 0x00 0x20>;
		phandle = <0x60>;
	};

	qos@ffac8000 {
		compatible = "syscon";
		reg = <0x00 0xffac8000 0x00 0x20>;
		phandle = <0x71>;
	};

	qos@ffac8080 {
		compatible = "syscon";
		reg = <0x00 0xffac8080 0x00 0x20>;
		phandle = <0x72>;
	};

	qos@ffad0000 {
		compatible = "syscon";
		reg = <0x00 0xffad0000 0x00 0x20>;
		phandle = <0x73>;
	};

	qos@ffad8080 {
		compatible = "syscon";
		reg = <0x00 0xffad8080 0x00 0x20>;
		phandle = <0x64>;
	};

	qos@ffae0000 {
		compatible = "syscon";
		reg = <0x00 0xffae0000 0x00 0x20>;
		phandle = <0x61>;
	};

	power-management@ff310000 {
		compatible = "rockchip,rk3399-pmu\0syscon\0simple-mfd";
		reg = <0x00 0xff310000 0x00 0x1000>;

		power-controller {
			compatible = "rockchip,rk3399-power-controller";
			#power-domain-cells = <0x01>;
			#address-cells = <0x01>;
			#size-cells = <0x00>;
			phandle = <0x1a>;

			power-domain@34 {
				reg = <0x22>;
				clocks = <0x08 0xe1 0x08 0x1dd>;
				pm_qos = <0x5b>;
			};

			power-domain@33 {
				reg = <0x21>;
				clocks = <0x08 0xdc 0x08 0x1e5>;
				pm_qos = <0x5c 0x5d>;
			};

			power-domain@31 {
				reg = <0x1f>;
				clocks = <0x08 0xeb 0x08 0x1ea>;
				pm_qos = <0x5e>;
			};

			power-domain@32 {
				reg = <0x20>;
				clocks = <0x08 0xed 0x08 0x1ec>;
				pm_qos = <0x5f 0x60>;
			};

			power-domain@35 {
				reg = <0x23>;
				clocks = <0x08 0xd0>;
				pm_qos = <0x61>;
			};

			power-domain@25 {
				reg = <0x19>;
				clocks = <0x08 0x16c>;
			};

			power-domain@23 {
				reg = <0x17>;
				clocks = <0x08 0xf0>;
				pm_qos = <0x62>;
			};

			power-domain@22 {
				reg = <0x16>;
				clocks = <0x08 0xd5 0x08 0x166>;
				pm_qos = <0x63>;
			};

			power-domain@14 {
				reg = <0x0e>;
				#address-cells = <0x01>;
				#size-cells = <0x00>;
				clocks = <0x08 0xc0>;
				pm_qos = <0x64 0x65 0x66 0x67>;

				power-domain@27 {
					reg = <0x1b>;
					clocks = <0x08 0x1ce 0x08 0x4c>;
					pm_qos = <0x68>;
				};
			};

			power-domain@28 {
				reg = <0x1c>;
				clocks = <0x08 0x1ee>;
				pm_qos = <0x69>;
			};

			power-domain@8 {
				reg = <0x08>;
				clocks = <0x08 0x7e 0x08 0x7d>;
			};

			power-domain@9 {
				reg = <0x09>;
				clocks = <0x08 0x80 0x08 0x7f>;
			};

			power-domain@24 {
				reg = <0x18>;
				clocks = <0x08 0xf4>;
				pm_qos = <0x6a 0x6b>;
			};

			power-domain@15 {
				reg = <0x0f>;
				#address-cells = <0x01>;
				#size-cells = <0x00>;

				power-domain@21 {
					reg = <0x15>;
					clocks = <0x08 0xde 0x08 0x1e7 0x08 0x172>;
					pm_qos = <0x6c>;
				};

				power-domain@19 {
					reg = <0x13>;
					clocks = <0x08 0xe5 0x08 0x1df>;
					pm_qos = <0x6d 0x6e>;
				};

				power-domain@20 {
					reg = <0x14>;
					clocks = <0x08 0xe6 0x08 0x1e0>;
					pm_qos = <0x6f 0x70>;
				};

				power-domain@16 {
					reg = <0x10>;
					#address-cells = <0x01>;
					#size-cells = <0x00>;

					power-domain@17 {
						reg = <0x11>;
						clocks = <0x08 0xd9 0x08 0x1d9>;
						pm_qos = <0x71 0x72>;
					};

					power-domain@18 {
						reg = <0x12>;
						clocks = <0x08 0xdb 0x08 0x1db>;
						pm_qos = <0x73>;
					};
				};
			};
		};
	};

	syscon@ff320000 {
		compatible = "rockchip,rk3399-pmugrf\0syscon\0simple-mfd";
		reg = <0x00 0xff320000 0x00 0x1000>;
		phandle = <0x8d>;

		io-domains {
			compatible = "rockchip,rk3399-pmu-io-voltage-domain";
			status = "okay";
			pmu1830-supply = <0x74>;
		};

		reboot-mode {
			compatible = "syscon-reboot-mode";
			offset = <0x300>;
			mode-charge = <0x5242c30b>;
			mode-fastboot = <0x5242c309>;
			mode-loader = <0x5242c301>;
			mode-normal = <0x5242c300>;
			mode-panic = <0x5242c307>;
			mode-recovery = <0x5242c303>;
			mode-ums = <0x5242c30c>;
		};

		pmu-pvtm {
			compatible = "rockchip,rk3399-pmu-pvtm";
			#address-cells = <0x01>;
			#size-cells = <0x00>;
			status = "disabled";

			pvtm@4 {
				reg = <0x04>;
				clocks = <0x75 0x07>;
				clock-names = "clk";
				resets = <0x75 0x1b>;
				reset-names = "rst";
			};
		};
	};

	spi@ff350000 {
		compatible = "rockchip,rk3399-spi\0rockchip,rk3066-spi";
		reg = <0x00 0xff350000 0x00 0x1000>;
		clocks = <0x75 0x03 0x75 0x1f>;
		clock-names = "spiclk\0apb_pclk";
		interrupts = <0x00 0x3c 0x04 0x00>;
		pinctrl-names = "default";
		pinctrl-0 = <0x76 0x77 0x78 0x79>;
		#address-cells = <0x01>;
		#size-cells = <0x00>;
		status = "disabled";
	};

	serial@ff370000 {
		compatible = "rockchip,rk3399-uart\0snps,dw-apb-uart";
		reg = <0x00 0xff370000 0x00 0x100>;
		clocks = <0x75 0x06 0x75 0x22>;
		clock-names = "baudclk\0apb_pclk";
		interrupts = <0x00 0x66 0x04 0x00>;
		reg-shift = <0x02>;
		reg-io-width = <0x04>;
		pinctrl-names = "default";
		pinctrl-0 = <0x7a>;
		status = "disabled";
	};

	i2c@ff3c0000 {
		compatible = "rockchip,rk3399-i2c";
		reg = <0x00 0xff3c0000 0x00 0x1000>;
		assigned-clocks = <0x75 0x09>;
		assigned-clock-rates = <0xbebc200>;
		clocks = <0x75 0x09 0x75 0x1b>;
		clock-names = "i2c\0pclk";
		interrupts = <0x00 0x39 0x04 0x00>;
		pinctrl-names = "default";
		pinctrl-0 = <0x7b>;
		#address-cells = <0x01>;
		#size-cells = <0x00>;
		status = "okay";
		clock-frequency = <0x61a80>;
		i2c-scl-rising-time-ns = <0xa8>;
		i2c-scl-falling-time-ns = <0x04>;

		pmic@1b {
			compatible = "rockchip,rk808";
			reg = <0x1b>;
			interrupt-parent = <0x7c>;
			interrupts = <0x15 0x08>;
			#clock-cells = <0x01>;
			clock-output-names = "xin32k\0rk808-clkout2";
			pinctrl-names = "default";
			pinctrl-0 = <0x7d>;
			rockchip,system-power-controller;
			wakeup-source;
			vcc1-supply = <0x7e>;
			vcc2-supply = <0x7e>;
			vcc3-supply = <0x7e>;
			vcc4-supply = <0x7e>;
			vcc6-supply = <0x7e>;
			vcc7-supply = <0x7e>;
			vcc8-supply = <0x7f>;
			vcc9-supply = <0x7e>;
			vcc10-supply = <0x7e>;
			vcc11-supply = <0x7e>;
			vcc12-supply = <0x7f>;
			vddio-supply = <0x80>;

			regulators {

				DCDC_REG1 {
					regulator-name = "vdd_center";
					regulator-always-on;
					regulator-boot-on;
					regulator-min-microvolt = <0xb71b0>;
					regulator-max-microvolt = <0x149970>;
					regulator-ramp-delay = <0x1771>;

					regulator-state-mem {
						regulator-off-in-suspend;
					};
				};

				DCDC_REG2 {
					regulator-name = "vdd_cpu_l";
					regulator-always-on;
					regulator-boot-on;
					regulator-min-microvolt = <0xb71b0>;
					regulator-max-microvolt = <0x149970>;
					regulator-ramp-delay = <0x1771>;
					phandle = <0x0e>;

					regulator-state-mem {
						regulator-off-in-suspend;
					};
				};

				DCDC_REG3 {
					regulator-name = "vcc_ddr";
					regulator-always-on;
					regulator-boot-on;

					regulator-state-mem {
						regulator-on-in-suspend;
					};
				};

				DCDC_REG4 {
					regulator-name = "vcc_1v8";
					regulator-always-on;
					regulator-boot-on;
					regulator-min-microvolt = <0x1b7740>;
					regulator-max-microvolt = <0x1b7740>;
					phandle = <0xc9>;

					regulator-state-mem {
						regulator-on-in-suspend;
						regulator-suspend-microvolt = <0x1b7740>;
					};
				};

				LDO_REG1 {
					regulator-name = "vcc1v8_dvp";
					regulator-always-on;
					regulator-boot-on;
					regulator-min-microvolt = <0x1b7740>;
					regulator-max-microvolt = <0x1b7740>;

					regulator-state-mem {
						regulator-off-in-suspend;
					};
				};

				LDO_REG2 {
					regulator-name = "vcc3v0_tp";
					regulator-always-on;
					regulator-boot-on;
					regulator-min-microvolt = <0x2dc6c0>;
					regulator-max-microvolt = <0x2dc6c0>;

					regulator-state-mem {
						regulator-off-in-suspend;
					};
				};

				LDO_REG3 {
					regulator-name = "vcc1v8_pmu";
					regulator-always-on;
					regulator-boot-on;
					regulator-min-microvolt = <0x1b7740>;
					regulator-max-microvolt = <0x1b7740>;
					phandle = <0x80>;

					regulator-state-mem {
						regulator-on-in-suspend;
						regulator-suspend-microvolt = <0x1b7740>;
					};
				};

				LDO_REG4 {
					regulator-name = "vcc_sdio";
					regulator-always-on;
					regulator-boot-on;
					regulator-min-microvolt = <0x1b7740>;
					regulator-max-microvolt = <0x325aa0>;
					phandle = <0x25>;

					regulator-state-mem {
						regulator-on-in-suspend;
						regulator-suspend-microvolt = <0x2dc6c0>;
					};
				};

				LDO_REG5 {
					regulator-name = "vcca3v0_codec";
					regulator-always-on;
					regulator-boot-on;
					regulator-min-microvolt = <0x2dc6c0>;
					regulator-max-microvolt = <0x2dc6c0>;

					regulator-state-mem {
						regulator-off-in-suspend;
					};
				};

				LDO_REG6 {
					regulator-name = "vcc_1v5";
					regulator-always-on;
					regulator-boot-on;
					regulator-min-microvolt = <0x16e360>;
					regulator-max-microvolt = <0x16e360>;

					regulator-state-mem {
						regulator-on-in-suspend;
						regulator-suspend-microvolt = <0x16e360>;
					};
				};

				LDO_REG7 {
					regulator-name = "vcca1v8_codec";
					regulator-always-on;
					regulator-boot-on;
					regulator-min-microvolt = <0x1b7740>;
					regulator-max-microvolt = <0x1b7740>;
					phandle = <0x95>;

					regulator-state-mem {
						regulator-off-in-suspend;
					};
				};

				LDO_REG8 {
					regulator-name = "vcc_3v0";
					regulator-always-on;
					regulator-boot-on;
					regulator-min-microvolt = <0x2dc6c0>;
					regulator-max-microvolt = <0x2dc6c0>;
					phandle = <0x74>;

					regulator-state-mem {
						regulator-on-in-suspend;
						regulator-suspend-microvolt = <0x2dc6c0>;
					};
				};

				SWITCH_REG1 {
					regulator-name = "vcc3v3_s3";
					regulator-always-on;
					regulator-boot-on;
					phandle = <0x1d>;

					regulator-state-mem {
						regulator-off-in-suspend;
					};
				};

				SWITCH_REG2 {
					regulator-name = "vcc3v3_s0";
					regulator-always-on;
					regulator-boot-on;

					regulator-state-mem {
						regulator-off-in-suspend;
					};
				};
			};
		};

		regulator@40 {
			compatible = "silergy,syr827";
			reg = <0x40>;
			fcs,suspend-voltage-selector = <0x01>;
			regulator-name = "vdd_cpu_b";
			regulator-min-microvolt = <0xadf34>;
			regulator-max-microvolt = <0x16e360>;
			regulator-ramp-delay = <0x3e8>;
			regulator-always-on;
			regulator-boot-on;
			vin-supply = <0x7e>;
			phandle = <0x12>;

			regulator-state-mem {
				regulator-off-in-suspend;
			};
		};

		regulator@41 {
			compatible = "silergy,syr828";
			reg = <0x41>;
			fcs,suspend-voltage-selector = <0x01>;
			regulator-name = "vdd_gpu";
			regulator-min-microvolt = <0xadf34>;
			regulator-max-microvolt = <0x16e360>;
			regulator-ramp-delay = <0x3e8>;
			regulator-always-on;
			regulator-boot-on;
			vin-supply = <0x7e>;
			phandle = <0xbb>;

			regulator-state-mem {
				regulator-off-in-suspend;
			};
		};
	};

	i2c@ff3d0000 {
		compatible = "rockchip,rk3399-i2c";
		reg = <0x00 0xff3d0000 0x00 0x1000>;
		assigned-clocks = <0x75 0x0a>;
		assigned-clock-rates = <0xbebc200>;
		clocks = <0x75 0x0a 0x75 0x1c>;
		clock-names = "i2c\0pclk";
		interrupts = <0x00 0x38 0x04 0x00>;
		pinctrl-names = "default";
		pinctrl-0 = <0x81>;
		#address-cells = <0x01>;
		#size-cells = <0x00>;
		status = "okay";
		i2c-scl-rising-time-ns = <0x1db>;
		i2c-scl-falling-time-ns = <0x1a>;

		fusb302@22 {
			compatible = "fcs,fusb302";
			reg = <0x22>;
			interrupt-parent = <0x7c>;
			interrupts = <0x02 0x08>;
			pinctrl-names = "default";
			pinctrl-0 = <0x82>;
			vbus-supply = <0x83>;
			status = "okay";

			ports {
				#address-cells = <0x01>;
				#size-cells = <0x00>;

				port@0 {
					reg = <0x00>;

					endpoint@0 {
						remote-endpoint = <0x84>;
						phandle = <0x2d>;
					};
				};
			};

			connector {
				compatible = "usb-c-connector";
				label = "USB-C";
				data-role = "dual";
				power-role = "dual";
				try-power-role = "sink";
				op-sink-microwatt = <0xf4240>;
				sink-pdos = <0x4019064>;
				source-pdos = <0x401912c>;
				displayport = <0x85>;

				altmodes {
					#address-cells = <0x01>;
					#size-cells = <0x00>;

					altmode@0 {
						reg = <0x00>;
						svid = <0xff01>;
						vdo = <0xffffffff>;
					};
				};

				ports {
					#address-cells = <0x01>;
					#size-cells = <0x00>;

					port@0 {
						reg = <0x00>;

						endpoint {
							remote-endpoint = <0x86>;
							phandle = <0x98>;
						};
					};

					port@1 {
						reg = <0x01>;

						endpoint {
							remote-endpoint = <0x87>;
							phandle = <0x99>;
						};
					};
				};
			};
		};
	};

	i2c@ff3e0000 {
		compatible = "rockchip,rk3399-i2c";
		reg = <0x00 0xff3e0000 0x00 0x1000>;
		assigned-clocks = <0x75 0x0b>;
		assigned-clock-rates = <0xbebc200>;
		clocks = <0x75 0x0b 0x75 0x1d>;
		clock-names = "i2c\0pclk";
		interrupts = <0x00 0x3a 0x04 0x00>;
		pinctrl-names = "default";
		pinctrl-0 = <0x88>;
		#address-cells = <0x01>;
		#size-cells = <0x00>;
		status = "disabled";
	};

	pwm@ff420000 {
		compatible = "rockchip,rk3399-pwm\0rockchip,rk3288-pwm";
		reg = <0x00 0xff420000 0x00 0x10>;
		#pwm-cells = <0x03>;
		pinctrl-names = "active";
		pinctrl-0 = <0x89>;
		clocks = <0x75 0x1e>;
		clock-names = "pwm";
		status = "okay";
	};

	pwm@ff420010 {
		compatible = "rockchip,rk3399-pwm\0rockchip,rk3288-pwm";
		reg = <0x00 0xff420010 0x00 0x10>;
		#pwm-cells = <0x03>;
		pinctrl-names = "active";
		pinctrl-0 = <0x8a>;
		clocks = <0x75 0x1e>;
		clock-names = "pwm";
		status = "disabled";
	};

	pwm@ff420020 {
		compatible = "rockchip,rk3399-pwm\0rockchip,rk3288-pwm";
		reg = <0x00 0xff420020 0x00 0x10>;
		#pwm-cells = <0x03>;
		pinctrl-names = "active";
		pinctrl-0 = <0x8b>;
		clocks = <0x75 0x1e>;
		clock-names = "pwm";
		status = "okay";
		phandle = <0xd0>;
	};

	pwm@ff420030 {
		compatible = "rockchip,rk3399-pwm\0rockchip,rk3288-pwm";
		reg = <0x00 0xff420030 0x00 0x10>;
		#pwm-cells = <0x03>;
		pinctrl-names = "active";
		pinctrl-0 = <0x8c>;
		clocks = <0x75 0x1e>;
		clock-names = "pwm";
		status = "disabled";
	};

	dfi@ff630000 {
		reg = <0x00 0xff630000 0x00 0x4000>;
		compatible = "rockchip,rk3399-dfi";
		rockchip,pmu = <0x8d>;
		clocks = <0x08 0x179>;
		clock-names = "pclk_ddr_mon";
		status = "disabled";
		phandle = <0x8e>;
	};

	dmc {
		compatible = "rockchip,rk3399-dmc";
		devfreq-events = <0x8e>;
		interrupts = <0x00 0x01 0x04 0x00>;
		clocks = <0x08 0xaa>;
		clock-names = "dmc_clk";
		ddr_timing = <0x8f>;
		status = "disabled";
		operating-points-v2 = <0x90>;
		phandle = <0xab>;
	};

	mpp-srv {
		compatible = "rockchip,mpp-service";
		rockchip,taskqueue-count = <0x02>;
		rockchip,resetgroup-count = <0x02>;
		status = "disabled";
		phandle = <0x92>;
	};

	video-codec@ff650000 {
		compatible = "rockchip,rk3399-vpu";
		reg = <0x00 0xff650000 0x00 0x800>;
		interrupts = <0x00 0x72 0x04 0x00 0x00 0x71 0x04 0x00>;
		interrupt-names = "vepu\0vdpu";
		clocks = <0x08 0xeb 0x08 0x1ea>;
		clock-names = "aclk\0hclk";
		iommus = <0x91>;
		power-domains = <0x1a 0x1f>;
		status = "disabled";
	};

	vepu@ff650000 {
		compatible = "rockchip,vpu-encoder-v2";
		reg = <0x00 0xff650000 0x00 0x400>;
		interrupts = <0x00 0x72 0x04 0x00>;
		interrupt-names = "irq_enc";
		clocks = <0x08 0xeb 0x08 0x1ea>;
		clock-names = "aclk_vcodec\0hclk_vcodec";
		resets = <0x08 0x53 0x08 0x51>;
		reset-names = "shared_video_h\0shared_video_a";
		iommus = <0x91>;
		rockchip,srv = <0x92>;
		rockchip,taskqueue-node = <0x00>;
		rockchip,resetgroup-node = <0x00>;
		power-domains = <0x1a 0x1f>;
		status = "disabled";
	};

	vdpu@ff650400 {
		compatible = "rockchip,vpu-decoder-v2";
		reg = <0x00 0xff650400 0x00 0x400>;
		interrupts = <0x00 0x71 0x04 0x00>;
		interrupt-names = "irq_dec";
		clocks = <0x08 0xeb 0x08 0x1ea>;
		clock-names = "aclk_vcodec\0hclk_vcodec";
		resets = <0x08 0x53 0x08 0x51>;
		reset-names = "shared_video_h\0shared_video_a";
		iommus = <0x91>;
		power-domains = <0x1a 0x1f>;
		rockchip,srv = <0x92>;
		rockchip,taskqueue-node = <0x00>;
		rockchip,resetgroup-node = <0x00>;
		status = "disabled";
	};

	iommu@ff650800 {
		compatible = "rockchip,iommu";
		reg = <0x00 0xff650800 0x00 0x40>;
		interrupts = <0x00 0x73 0x04 0x00>;
		interrupt-names = "vpu_mmu";
		clocks = <0x08 0xeb 0x08 0x1ea>;
		clock-names = "aclk\0iface";
		#iommu-cells = <0x00>;
		power-domains = <0x1a 0x1f>;
		status = "disabled";
		phandle = <0x91>;
	};

	video-codec@ff660000 {
		compatible = "rockchip,rk3399-vdec";
		reg = <0x00 0xff660000 0x00 0x400>;
		interrupts = <0x00 0x74 0x04 0x00>;
		clocks = <0x08 0xed 0x08 0x1ec 0x08 0x9f 0x08 0x9e>;
		clock-names = "axi\0ahb\0cabac\0core";
		iommus = <0x93>;
		power-domains = <0x1a 0x20>;
		status = "disabled";
	};

	rkvdec@ff660000 {
		compatible = "rockchip,rkv-decoder-rk3399";
		reg = <0x00 0xff660000 0x00 0x400>;
		interrupts = <0x00 0x74 0x04 0x00>;
		interrupt-names = "irq_dec";
		clocks = <0x08 0xed 0x08 0x1ec 0x08 0x9f 0x08 0x9e>;
		clock-names = "aclk_vcodec\0hclk_vcodec\0clk_cabac\0clk_core";
		resets = <0x08 0x5b 0x08 0x59 0x08 0x5a 0x08 0x58 0x08 0x5d 0x08 0x5c>;
		reset-names = "video_h\0video_a\0niu_h\0niu_a\0video_cabac\0video_core";
		iommus = <0x93>;
		rockchip,srv = <0x92>;
		rockchip,taskqueue-node = <0x01>;
		rockchip,resetgroup-node = <0x01>;
		power-domains = <0x1a 0x20>;
		status = "disabled";
	};

	iommu@ff660480 {
		compatible = "rockchip,iommu";
		reg = <0x00 0xff660480 0x00 0x40 0x00 0xff6604c0 0x00 0x40>;
		interrupts = <0x00 0x75 0x04 0x00>;
		interrupt-names = "vdec_mmu";
		clocks = <0x08 0xed 0x08 0x1ec>;
		clock-names = "aclk\0iface";
		power-domains = <0x1a 0x20>;
		#iommu-cells = <0x00>;
		status = "disabled";
		phandle = <0x93>;
	};

	iep@ff670000 {
		compatible = "rockchip,iep";
		iommu_enabled = <0x01>;
		iommus = <0x94>;
		reg = <0x00 0xff670000 0x00 0x800>;
		interrupts = <0x00 0x2a 0x04 0x00>;
		clocks = <0x08 0xe1 0x08 0x1dd>;
		clock-names = "aclk_iep\0hclk_iep";
		power-domains = <0x1a 0x22>;
		allocator = <0x01>;
		version = <0x02>;
		status = "disabled";
	};

	iommu@ff670800 {
		compatible = "rockchip,iommu";
		reg = <0x00 0xff670800 0x00 0x40>;
		interrupts = <0x00 0x2a 0x04 0x00>;
		interrupt-names = "iep_mmu";
		clocks = <0x08 0xe1 0x08 0x1dd>;
		clock-names = "aclk\0iface";
		power-domains = <0x1a 0x22>;
		#iommu-cells = <0x00>;
		status = "disabled";
		phandle = <0x94>;
	};

	rga@ff680000 {
		compatible = "rockchip,rk3399-rga";
		reg = <0x00 0xff680000 0x00 0x10000>;
		interrupts = <0x00 0x37 0x04 0x00>;
		clocks = <0x08 0xdc 0x08 0x1e5 0x08 0x6d>;
		clock-names = "aclk\0hclk\0sclk";
		resets = <0x08 0x6a 0x08 0x67 0x08 0x69>;
		reset-names = "core\0axi\0ahb";
		power-domains = <0x1a 0x21>;
	};

	efuse@ff690000 {
		compatible = "rockchip,rk3399-efuse";
		reg = <0x00 0xff690000 0x00 0x80>;
		#address-cells = <0x01>;
		#size-cells = <0x01>;
		clocks = <0x08 0x17d>;
		clock-names = "pclk_efuse";

		specification-serial-number@6 {
			reg = <0x06 0x01>;
			bits = <0x00 0x05>;
			phandle = <0xc2>;
		};

		cpu-id@7 {
			reg = <0x07 0x10>;
		};

		cpu-leakage@17 {
			reg = <0x17 0x01>;
			phandle = <0xc4>;
		};

		gpu-leakage@18 {
			reg = <0x18 0x01>;
			phandle = <0xc5>;
		};

		center-leakage@19 {
			reg = <0x19 0x01>;
		};

		cpu-leakage@1a {
			reg = <0x1a 0x01>;
			phandle = <0xc1>;
		};

		logic-leakage@1b {
			reg = <0x1b 0x01>;
		};

		wafer-info@1c {
			reg = <0x1c 0x01>;
		};

		customer-demand@22 {
			reg = <0x22 0x01>;
			bits = <0x04 0x04>;
			phandle = <0xc3>;
		};
	};

	pmu-clock-controller@ff750000 {
		compatible = "rockchip,rk3399-pmucru";
		reg = <0x00 0xff750000 0x00 0x1000>;
		rockchip,grf = <0x8d>;
		#clock-cells = <0x01>;
		#reset-cells = <0x01>;
		assigned-clocks = <0x75 0x01>;
		assigned-clock-rates = <0x284af100>;
		phandle = <0x75>;
	};

	clock-controller@ff760000 {
		compatible = "rockchip,rk3399-cru";
		reg = <0x00 0xff760000 0x00 0x1000>;
		rockchip,grf = <0x1b>;
		#clock-cells = <0x01>;
		#reset-cells = <0x01>;
		assigned-clocks = <0x08 0x05 0x08 0x04 0x08 0x06 0x08 0xc0 0x08 0x1c0 0x08 0x140 0x08 0xc2 0x08 0x1c1 0x08 0x142 0x08 0xc9 0x08 0x1c2 0x08 0x143 0x08 0xe3 0x08 0xde 0x08 0x106 0x08 0x178>;
		assigned-clock-rates = <0x2367b880 0x2faf0800 0x3b9aca00 0x8f0d180 0x47868c0 0x23c3460 0x5f5e100 0x5f5e100 0x2faf080 0x23c34600 0x5f5e100 0x2faf080 0x17d78400 0x17d78400 0xbebc200 0xbebc200>;
		phandle = <0x08>;
	};

	syscon@ff770000 {
		compatible = "rockchip,rk3399-grf\0syscon\0simple-mfd";
		reg = <0x00 0xff770000 0x00 0x10000>;
		#address-cells = <0x01>;
		#size-cells = <0x01>;
		phandle = <0x1b>;

		io-domains {
			compatible = "rockchip,rk3399-io-voltage-domain";
			status = "okay";
			bt656-supply = <0x74>;
			audio-supply = <0x95>;
			sdmmc-supply = <0x25>;
			gpio1830-supply = <0x74>;
		};

		mipi-dphy-rx0 {
			compatible = "rockchip,rk3399-mipi-dphy";
			clocks = <0x08 0x77 0x08 0xa5 0x08 0x16f>;
			clock-names = "dphy-ref\0dphy-cfg\0grf";
			power-domains = <0x1a 0x0f>;
			#phy-cells = <0x00>;
			status = "disabled";
		};

		usb2-phy@e450 {
			compatible = "rockchip,rk3399-usb2phy";
			reg = <0xe450 0x10>;
			clocks = <0x08 0x7b>;
			clock-names = "phyclk";
			#clock-cells = <0x00>;
			clock-output-names = "clk_usbphy0_480m";
			status = "okay";
			phandle = <0x27>;

			host-port {
				#phy-cells = <0x00>;
				interrupts = <0x00 0x1b 0x04 0x00>;
				interrupt-names = "linestate";
				status = "okay";
				phy-supply = <0x96>;
				phandle = <0x28>;
			};

			otg-port {
				#phy-cells = <0x00>;
				interrupts = <0x00 0x67 0x04 0x00 0x00 0x68 0x04 0x00 0x00 0x6a 0x04 0x00>;
				interrupt-names = "otg-bvalid\0otg-id\0linestate";
				status = "okay";
				phandle = <0x2b>;
			};
		};

		usb2-phy@e460 {
			compatible = "rockchip,rk3399-usb2phy";
			reg = <0xe460 0x10>;
			clocks = <0x08 0x7c>;
			clock-names = "phyclk";
			#clock-cells = <0x00>;
			clock-output-names = "clk_usbphy1_480m";
			status = "okay";
			phandle = <0x29>;

			host-port {
				#phy-cells = <0x00>;
				interrupts = <0x00 0x1f 0x04 0x00>;
				interrupt-names = "linestate";
				status = "okay";
				phy-supply = <0x96>;
				phandle = <0x2a>;
			};

			otg-port {
				#phy-cells = <0x00>;
				interrupts = <0x00 0x6c 0x04 0x00 0x00 0x6d 0x04 0x00 0x00 0x6f 0x04 0x00>;
				interrupt-names = "otg-bvalid\0otg-id\0linestate";
				status = "okay";
				phandle = <0x2e>;
			};
		};

		phy@f780 {
			compatible = "rockchip,rk3399-emmc-phy";
			reg = <0xf780 0x24>;
			clocks = <0x97>;
			clock-names = "emmcclk";
			drive-impedance-ohm = <0x32>;
			#phy-cells = <0x00>;
			status = "okay";
			phandle = <0x26>;
		};

		pcie-phy {
			compatible = "rockchip,rk3399-pcie-phy";
			clocks = <0x08 0x8a>;
			clock-names = "refclk";
			#phy-cells = <0x01>;
			resets = <0x08 0x87>;
			reset-names = "phy";
			status = "disabled";
			phandle = <0x19>;
		};

		pvtm {
			compatible = "rockchip,rk3399-pvtm";
			#address-cells = <0x01>;
			#size-cells = <0x00>;
			status = "disabled";

			pvtm@0 {
				reg = <0x00>;
				clocks = <0x08 0x73>;
				clock-names = "clk";
				resets = <0x08 0x1f>;
				reset-names = "rst";
			};

			pvtm@1 {
				reg = <0x01>;
				clocks = <0x08 0x74>;
				clock-names = "clk";
				resets = <0x08 0x2f>;
				reset-names = "rst";
			};

			pvtm@2 {
				reg = <0x02>;
				clocks = <0x08 0x76>;
				clock-names = "clk";
				resets = <0x08 0x4f>;
				reset-names = "rst";
			};

			pvtm@3 {
				reg = <0x03>;
				clocks = <0x08 0x75>;
				clock-names = "clk";
				resets = <0x08 0x123>;
				reset-names = "rst";
			};
		};
	};

	phy@ff7c0000 {
		compatible = "rockchip,rk3399-typec-phy";
		reg = <0x00 0xff7c0000 0x00 0x40000>;
		clocks = <0x08 0x7e 0x08 0x7d>;
		clock-names = "tcpdcore\0tcpdphy-ref";
		assigned-clocks = <0x08 0x7e>;
		assigned-clock-rates = <0x2faf080>;
		power-domains = <0x1a 0x08>;
		resets = <0x08 0x95 0x08 0x94 0x08 0x14c>;
		reset-names = "uphy\0uphy-pipe\0uphy-tcphy";
		rockchip,grf = <0x1b>;
		status = "okay";
		svid = <0xff01>;
		orientation-switch;

		dp-port {
			#phy-cells = <0x00>;
			phandle = <0x30>;
		};

		usb3-port {
			#phy-cells = <0x00>;
			phandle = <0x2c>;
		};

		port {
			#address-cells = <0x01>;
			#size-cells = <0x00>;

			endpoint@0 {
				reg = <0x00>;
				remote-endpoint = <0x98>;
				phandle = <0x86>;
			};

			endpoint@1 {
				reg = <0x01>;
				remote-endpoint = <0x99>;
				phandle = <0x87>;
			};
		};
	};

	phy@ff800000 {
		compatible = "rockchip,rk3399-typec-phy";
		reg = <0x00 0xff800000 0x00 0x40000>;
		clocks = <0x08 0x80 0x08 0x7f>;
		clock-names = "tcpdcore\0tcpdphy-ref";
		assigned-clocks = <0x08 0x80>;
		assigned-clock-rates = <0x2faf080>;
		power-domains = <0x1a 0x09>;
		resets = <0x08 0x9d 0x08 0x9c 0x08 0x14d>;
		reset-names = "uphy\0uphy-pipe\0uphy-tcphy";
		rockchip,grf = <0x1b>;
		status = "okay";

		dp-port {
			#phy-cells = <0x00>;
		};

		usb3-port {
			#phy-cells = <0x00>;
			phandle = <0x2f>;
		};
	};

	watchdog@ff848000 {
		compatible = "snps,dw-wdt";
		reg = <0x00 0xff848000 0x00 0x100>;
		clocks = <0x08 0x17c>;
		interrupts = <0x00 0x78 0x04 0x00>;
	};

	rktimer@ff850000 {
		compatible = "rockchip,rk3399-timer";
		reg = <0x00 0xff850000 0x00 0x1000>;
		interrupts = <0x00 0x51 0x04 0x00>;
		clocks = <0x08 0x168 0x08 0x5a>;
		clock-names = "pclk\0timer";
	};

	spdif@ff870000 {
		compatible = "rockchip,rk3399-spdif";
		reg = <0x00 0xff870000 0x00 0x1000>;
		interrupts = <0x00 0x42 0x04 0x00>;
		dmas = <0x50 0x07>;
		dma-names = "tx";
		clock-names = "mclk\0hclk";
		clocks = <0x08 0x55 0x08 0x1d7>;
		pinctrl-names = "default";
		pinctrl-0 = <0x9a>;
		power-domains = <0x1a 0x1c>;
		#sound-dai-cells = <0x00>;
		status = "disabled";
	};

	i2s@ff880000 {
		compatible = "rockchip,rk3399-i2s\0rockchip,rk3066-i2s";
		reg = <0x00 0xff880000 0x00 0x1000>;
		rockchip,grf = <0x1b>;
		interrupts = <0x00 0x27 0x04 0x00>;
		dmas = <0x50 0x00 0x50 0x01>;
		dma-names = "tx\0rx";
		clock-names = "i2s_clk\0i2s_hclk";
		clocks = <0x08 0x56 0x08 0x1d4>;
		resets = <0x08 0xe0 0x08 0xc2>;
		reset-names = "reset-m\0reset-h";
		pinctrl-names = "default";
		pinctrl-0 = <0x9b>;
		power-domains = <0x1a 0x1c>;
		#sound-dai-cells = <0x00>;
		status = "disabled";
	};

	i2s@ff890000 {
		compatible = "rockchip,rk3399-i2s\0rockchip,rk3066-i2s";
		reg = <0x00 0xff890000 0x00 0x1000>;
		interrupts = <0x00 0x28 0x04 0x00>;
		dmas = <0x50 0x02 0x50 0x03>;
		dma-names = "tx\0rx";
		clock-names = "i2s_clk\0i2s_hclk";
		clocks = <0x08 0x57 0x08 0x1d5>;
		resets = <0x08 0xe1 0x08 0xc3>;
		reset-names = "reset-m\0reset-h";
		pinctrl-names = "default";
		pinctrl-0 = <0x9c>;
		power-domains = <0x1a 0x1c>;
		#sound-dai-cells = <0x00>;
		status = "disabled";
	};

	i2s@ff8a0000 {
		compatible = "rockchip,rk3399-i2s\0rockchip,rk3066-i2s";
		reg = <0x00 0xff8a0000 0x00 0x1000>;
		interrupts = <0x00 0x29 0x04 0x00>;
		dmas = <0x50 0x04 0x50 0x05>;
		dma-names = "tx\0rx";
		clock-names = "i2s_clk\0i2s_hclk";
		clocks = <0x08 0x58 0x08 0x1d6>;
		resets = <0x08 0xe2 0x08 0xc4>;
		reset-names = "reset-m\0reset-h";
		power-domains = <0x1a 0x1c>;
		#sound-dai-cells = <0x00>;
		status = "okay";
		phandle = <0xae>;
	};

	rng@ff8b8000 {
		compatible = "rockchip,cryptov1-rng";
		reg = <0x00 0xff8b8000 0x00 0x1000>;
		clocks = <0x08 0x86 0x08 0x1d3>;
		clock-names = "clk_crypto\0hclk_crypto";
		assigned-clocks = <0x08 0x86 0x08 0x1d3>;
		assigned-clock-rates = <0x8f0d180 0x5f5e100>;
		status = "disabled";
	};

	vop@ff8f0000 {
		compatible = "rockchip,rk3399-vop-lit";
		reg = <0x00 0xff8f0000 0x00 0x600 0x00 0xff8f1c00 0x00 0x200 0x00 0xff8f2000 0x00 0x400>;
		reg-names = "regs\0cabc_lut\0gamma_lut";
		interrupts = <0x00 0x77 0x04 0x00>;
		clocks = <0x08 0xdb 0x08 0xb5 0x08 0x1db 0x08 0xb7>;
		clock-names = "aclk_vop\0dclk_vop\0hclk_vop\0dclk_source";
		iommus = <0x9d>;
		power-domains = <0x1a 0x12>;
		resets = <0x08 0x113 0x08 0x117 0x08 0x119>;
		reset-names = "axi\0ahb\0dclk";
		status = "okay";

		port {
			#address-cells = <0x01>;
			#size-cells = <0x00>;
			phandle = <0x13>;

			endpoint@0 {
				reg = <0x00>;
				remote-endpoint = <0x9e>;
				phandle = <0xb4>;
			};

			endpoint@1 {
				reg = <0x01>;
				remote-endpoint = <0x9f>;
				phandle = <0xb9>;
			};

			endpoint@2 {
				reg = <0x02>;
				remote-endpoint = <0xa0>;
				phandle = <0xb2>;
			};

			endpoint@3 {
				reg = <0x03>;
				remote-endpoint = <0xa1>;
				phandle = <0xb6>;
			};

			endpoint@4 {
				reg = <0x04>;
				remote-endpoint = <0xa2>;
				phandle = <0x32>;
			};
		};
	};

	voppwm@ff8f01a0 {
		compatible = "rockchip,vop-pwm";
		reg = <0x00 0xff8f01a0 0x00 0x10>;
		#pwm-cells = <0x03>;
		pinctrl-names = "active";
		pinctrl-0 = <0xa3>;
		clocks = <0x08 0x6c>;
		clock-names = "pwm";
		status = "disabled";
	};

	iommu@ff8f3f00 {
		compatible = "rockchip,iommu";
		reg = <0x00 0xff8f3f00 0x00 0x100>;
		interrupts = <0x00 0x77 0x04 0x00>;
		interrupt-names = "vopl_mmu";
		clocks = <0x08 0xdb 0x08 0x1db>;
		clock-names = "aclk\0iface";
		power-domains = <0x1a 0x12>;
		#iommu-cells = <0x00>;
		rockchip,disable-device-link-resume;
		status = "okay";
		phandle = <0x9d>;
	};

	vop@ff900000 {
		compatible = "rockchip,rk3399-vop-big";
		reg = <0x00 0xff900000 0x00 0x600 0x00 0xff901c00 0x00 0x200 0x00 0xff902000 0x00 0x1000>;
		reg-names = "regs\0cabc_lut\0gamma_lut";
		interrupts = <0x00 0x76 0x04 0x00>;
		clocks = <0x08 0xd9 0x08 0xb4 0x08 0x1d9 0x08 0xb6>;
		clock-names = "aclk_vop\0dclk_vop\0hclk_vop\0dclk_source";
		iommus = <0xa4>;
		power-domains = <0x1a 0x11>;
		resets = <0x08 0x112 0x08 0x116 0x08 0x118>;
		reset-names = "axi\0ahb\0dclk";
		status = "okay";

		port {
			#address-cells = <0x01>;
			#size-cells = <0x00>;
			phandle = <0x14>;

			endpoint@0 {
				reg = <0x00>;
				remote-endpoint = <0xa5>;
				phandle = <0xb8>;
			};

			endpoint@1 {
				reg = <0x01>;
				remote-endpoint = <0xa6>;
				phandle = <0xb3>;
			};

			endpoint@2 {
				reg = <0x02>;
				remote-endpoint = <0xa7>;
				phandle = <0xb1>;
			};

			endpoint@3 {
				reg = <0x03>;
				remote-endpoint = <0xa8>;
				phandle = <0xb5>;
			};

			endpoint@4 {
				reg = <0x04>;
				remote-endpoint = <0xa9>;
				phandle = <0x31>;
			};
		};
	};

	voppwm@ff9001a0 {
		compatible = "rockchip,vop-pwm";
		reg = <0x00 0xff9001a0 0x00 0x10>;
		#pwm-cells = <0x03>;
		pinctrl-names = "active";
		pinctrl-0 = <0xaa>;
		clocks = <0x08 0x6b>;
		clock-names = "pwm";
		status = "disabled";
	};

	iommu@ff903f00 {
		compatible = "rockchip,iommu";
		reg = <0x00 0xff903f00 0x00 0x100>;
		interrupts = <0x00 0x76 0x04 0x00>;
		interrupt-names = "vopb_mmu";
		clocks = <0x08 0xd9 0x08 0x1d9>;
		clock-names = "aclk\0iface";
		power-domains = <0x1a 0x11>;
		#iommu-cells = <0x00>;
		rockchip,disable-device-link-resume;
		status = "okay";
		phandle = <0xa4>;
	};

	rkisp1@ff910000 {
		compatible = "rockchip,rk3399-rkisp1";
		reg = <0x00 0xff910000 0x00 0x4000>;
		interrupts = <0x00 0x2b 0x04 0x00>;
		interrupt-names = "isp_irq";
		clocks = <0x08 0x6e 0x08 0xe5 0x08 0x1df 0x08 0xe9 0x08 0x1e3>;
		clock-names = "clk_isp\0aclk_isp\0hclk_isp\0aclk_isp_wrap\0hclk_isp_wrap";
		devfreq = <0xab>;
		power-domains = <0x1a 0x13>;
		iommus = <0xac>;
		status = "disabled";
	};

	iommu@ff914000 {
		compatible = "rockchip,iommu";
		reg = <0x00 0xff914000 0x00 0x100 0x00 0xff915000 0x00 0x100>;
		interrupts = <0x00 0x2b 0x04 0x00>;
		interrupt-names = "isp0_mmu";
		clocks = <0x08 0xe9 0x08 0x1e3>;
		clock-names = "aclk\0iface";
		#iommu-cells = <0x00>;
		power-domains = <0x1a 0x13>;
		rockchip,disable-mmu-reset;
		status = "disabled";
		phandle = <0xac>;
	};

	rkisp1@ff920000 {
		compatible = "rockchip,rk3399-rkisp1";
		reg = <0x00 0xff920000 0x00 0x4000>;
		interrupts = <0x00 0x2c 0x04 0x00>;
		interrupt-names = "isp_irq";
		clocks = <0x08 0x6f 0x08 0xe6 0x08 0x1e0 0x08 0xea 0x08 0x1e4 0x08 0x17b>;
		clock-names = "clk_isp\0aclk_isp\0hclk_isp\0aclk_isp_wrap\0hclk_isp_wrap\0pclk_isp_wrap";
		devfreq = <0xab>;
		power-domains = <0x1a 0x14>;
		iommus = <0xad>;
		status = "disabled";
	};

	iommu@ff924000 {
		compatible = "rockchip,iommu";
		reg = <0x00 0xff924000 0x00 0x100 0x00 0xff925000 0x00 0x100>;
		interrupts = <0x00 0x2c 0x04 0x00>;
		interrupt-names = "isp1_mmu";
		clocks = <0x08 0xea 0x08 0x1e4>;
		clock-names = "aclk\0iface";
		#iommu-cells = <0x00>;
		power-domains = <0x1a 0x14>;
		rockchip,disable-mmu-reset;
		status = "disabled";
		phandle = <0xad>;
	};

	hdmi-sound {
		compatible = "simple-audio-card";
		simple-audio-card,format = "i2s";
		simple-audio-card,mclk-fs = <0x100>;
		simple-audio-card,name = "hdmi-sound";
		status = "okay";

		simple-audio-card,cpu {
			sound-dai = <0xae>;
		};

		simple-audio-card,codec {
			sound-dai = <0xaf>;
		};
	};

	hdmi@ff940000 {
		compatible = "rockchip,rk3399-dw-hdmi";
		reg = <0x00 0xff940000 0x00 0x20000>;
		interrupts = <0x00 0x17 0x04 0x00>;
		clocks = <0x08 0x174 0x08 0x71 0x08 0x70 0x08 0x16f 0x08 0x07>;
		clock-names = "iahb\0isfr\0cec\0grf\0vpll";
		power-domains = <0x1a 0x15>;
		reg-io-width = <0x04>;
		rockchip,grf = <0x1b>;
		#sound-dai-cells = <0x00>;
		pinctrl-names = "default";
		pinctrl-0 = <0xb0>;
		status = "okay";
		phandle = <0xaf>;

		ports {

			port {
				#address-cells = <0x01>;
				#size-cells = <0x00>;

				endpoint@0 {
					reg = <0x00>;
					remote-endpoint = <0xb1>;
					phandle = <0xa7>;
				};

				endpoint@1 {
					reg = <0x01>;
					remote-endpoint = <0xb2>;
					phandle = <0xa0>;
				};
			};
		};
	};

	dsi@ff960000 {
		compatible = "rockchip,rk3399-mipi-dsi\0snps,dw-mipi-dsi";
		reg = <0x00 0xff960000 0x00 0x8000>;
		interrupts = <0x00 0x2d 0x04 0x00>;
		clocks = <0x08 0xa2 0x08 0x170 0x08 0xa3 0x08 0x16f>;
		clock-names = "ref\0pclk\0phy_cfg\0grf";
		power-domains = <0x1a 0x0f>;
		resets = <0x08 0xfb>;
		reset-names = "apb";
		rockchip,grf = <0x1b>;
		#address-cells = <0x01>;
		#size-cells = <0x00>;
		status = "disabled";

		ports {
			#address-cells = <0x01>;
			#size-cells = <0x00>;

			port@0 {
				reg = <0x00>;
				#address-cells = <0x01>;
				#size-cells = <0x00>;

				endpoint@0 {
					reg = <0x00>;
					remote-endpoint = <0xb3>;
					phandle = <0xa6>;
				};

				endpoint@1 {
					reg = <0x01>;
					remote-endpoint = <0xb4>;
					phandle = <0x9e>;
				};
			};
		};
	};

	dsi@ff968000 {
		compatible = "rockchip,rk3399-mipi-dsi\0snps,dw-mipi-dsi";
		reg = <0x00 0xff968000 0x00 0x8000>;
		interrupts = <0x00 0x2e 0x04 0x00>;
		clocks = <0x08 0xa2 0x08 0x171 0x08 0xa4 0x08 0x16f>;
		clock-names = "ref\0pclk\0phy_cfg\0grf";
		power-domains = <0x1a 0x0f>;
		resets = <0x08 0xfc>;
		reset-names = "apb";
		rockchip,grf = <0x1b>;
		#address-cells = <0x01>;
		#size-cells = <0x00>;
		status = "disabled";

		ports {
			#address-cells = <0x01>;
			#size-cells = <0x00>;

			port@0 {
				reg = <0x00>;
				#address-cells = <0x01>;
				#size-cells = <0x00>;

				endpoint@0 {
					reg = <0x00>;
					remote-endpoint = <0xb5>;
					phandle = <0xa8>;
				};

				endpoint@1 {
					reg = <0x01>;
					remote-endpoint = <0xb6>;
					phandle = <0xa1>;
				};
			};
		};
	};

	mipi-dphy-tx1rx1@ff968000 {
		compatible = "rockchip,rk3399-mipi-dphy";
		reg = <0x00 0xff968000 0x00 0x8000>;
		clocks = <0x08 0x77 0x08 0xa4 0x08 0x16f 0x08 0x171>;
		clock-names = "dphy-ref\0dphy-cfg\0grf\0pclk_mipi_dsi";
		rockchip,grf = <0x1b>;
		power-domains = <0x1a 0x0f>;
		status = "disabled";
	};

	edp@ff970000 {
		compatible = "rockchip,rk3399-edp";
		reg = <0x00 0xff970000 0x00 0x8000>;
		interrupts = <0x00 0x0a 0x04 0x00>;
		clocks = <0x08 0x16a 0x08 0x16c 0x08 0x16f>;
		clock-names = "dp\0pclk\0grf";
		pinctrl-names = "default";
		pinctrl-0 = <0xb7>;
		power-domains = <0x1a 0x19>;
		resets = <0x08 0x11d>;
		reset-names = "dp";
		rockchip,grf = <0x1b>;
		status = "disabled";

		ports {
			#address-cells = <0x01>;
			#size-cells = <0x00>;

			port@0 {
				reg = <0x00>;
				#address-cells = <0x01>;
				#size-cells = <0x00>;

				endpoint@0 {
					reg = <0x00>;
					remote-endpoint = <0xb8>;
					phandle = <0xa5>;
				};

				endpoint@1 {
					reg = <0x01>;
					remote-endpoint = <0xb9>;
					phandle = <0x9f>;
				};
			};
		};
	};

	gpu@ff9a0000 {
		compatible = "arm,malit860\0arm,malit86x\0arm,malit8xx\0arm,mali-midgard";
		reg = <0x00 0xff9a0000 0x00 0x10000>;
		interrupts = <0x00 0x14 0x04 0x00 0x00 0x15 0x04 0x00 0x00 0x13 0x04 0x00>;
		interrupt-names = "job\0mmu\0gpu";
		clocks = <0x08 0xd0>;
		clock-names = "clk_mali";
		#cooling-cells = <0x02>;
		power-domains = <0x1a 0x23>;
		power-off-delay-ms = <0xc8>;
		upthreshold = <0x28>;
		downdifferential = <0x0a>;
		status = "okay";
		operating-points-v2 = <0xba>;
		mali-supply = <0xbb>;

		power_model {
			compatible = "arm,mali-simple-power-model";
			static-coefficient = <0x64578>;
			dynamic-coefficient = <0x2dd>;
			ts = <0x7d00 0x125c 0xffffffb0 0x02>;
			thermal-zone = "gpu-thermal";
		};
	};

	nocp-cci-msch0@ffa86000 {
		compatible = "rockchip,rk3399-nocp";
		reg = <0x00 0xffa86000 0x00 0x400>;
	};

	nocp-gpu-msch0@ffa86400 {
		compatible = "rockchip,rk3399-nocp";
		reg = <0x00 0xffa86400 0x00 0x400>;
	};

	nocp-hp-msch0@ffa86800 {
		compatible = "rockchip,rk3399-nocp";
		reg = <0x00 0xffa86800 0x00 0x400>;
	};

	nocp-lp-msch0@ffa86c00 {
		compatible = "rockchip,rk3399-nocp";
		reg = <0x00 0xffa86c00 0x00 0x400>;
	};

	nocp-video-msch0@ffa87000 {
		compatible = "rockchip,rk3399-nocp";
		reg = <0x00 0xffa87000 0x00 0x400>;
	};

	nocp-vio0-msch0@ffa87400 {
		compatible = "rockchip,rk3399-nocp";
		reg = <0x00 0xffa87400 0x00 0x400>;
	};

	nocp-vio1-msch0@ffa87800 {
		compatible = "rockchip,rk3399-nocp";
		reg = <0x00 0xffa87800 0x00 0x400>;
	};

	nocp-cci-msch1@ffa8e000 {
		compatible = "rockchip,rk3399-nocp";
		reg = <0x00 0xffa8e000 0x00 0x400>;
	};

	nocp-gpu-msch1@ffa8e400 {
		compatible = "rockchip,rk3399-nocp";
		reg = <0x00 0xffa8e400 0x00 0x400>;
	};

	nocp-hp-msch1@ffa8e800 {
		compatible = "rockchip,rk3399-nocp";
		reg = <0x00 0xffa8e800 0x00 0x400>;
	};

	nocp-lp-msch1@ffa8ec00 {
		compatible = "rockchip,rk3399-nocp";
		reg = <0x00 0xffa8ec00 0x00 0x400>;
	};

	nocp-video-msch1@ffa8f000 {
		compatible = "rockchip,rk3399-nocp";
		reg = <0x00 0xffa8f000 0x00 0x400>;
	};

	nocp-vio0-msch1@ffa8f400 {
		compatible = "rockchip,rk3399-nocp";
		reg = <0x00 0xffa8f400 0x00 0x400>;
	};

	nocp-vio1-msch1@ffa8f800 {
		compatible = "rockchip,rk3399-nocp";
		reg = <0x00 0xffa8f800 0x00 0x400>;
	};

	rockchip-system-monitor {
		compatible = "rockchip,system-monitor";
		rockchip,thermal-zone = "soc-thermal";
		rockchip,polling-delay = <0xc8>;
	};

	pinctrl {
		compatible = "rockchip,rk3399-pinctrl";
		rockchip,grf = <0x1b>;
		rockchip,pmu = <0x8d>;
		#address-cells = <0x02>;
		#size-cells = <0x02>;
		ranges;

		gpio0@ff720000 {
			compatible = "rockchip,gpio-bank";
			reg = <0x00 0xff720000 0x00 0x100>;
			clocks = <0x75 0x17>;
			interrupts = <0x00 0x0e 0x04 0x00>;
			gpio-controller;
			#gpio-cells = <0x02>;
			interrupt-controller;
			#interrupt-cells = <0x02>;
			phandle = <0xc7>;
		};

		gpio1@ff730000 {
			compatible = "rockchip,gpio-bank";
			reg = <0x00 0xff730000 0x00 0x100>;
			clocks = <0x75 0x18>;
			interrupts = <0x00 0x0f 0x04 0x00>;
			gpio-controller;
			#gpio-cells = <0x02>;
			interrupt-controller;
			#interrupt-cells = <0x02>;
			phandle = <0x7c>;
		};

		gpio2@ff780000 {
			compatible = "rockchip,gpio-bank";
			reg = <0x00 0xff780000 0x00 0x100>;
			clocks = <0x08 0x150>;
			interrupts = <0x00 0x10 0x04 0x00>;
			gpio-controller;
			#gpio-cells = <0x02>;
			interrupt-controller;
			#interrupt-cells = <0x02>;
			phandle = <0xcd>;
		};

		gpio3@ff788000 {
			compatible = "rockchip,gpio-bank";
			reg = <0x00 0xff788000 0x00 0x100>;
			clocks = <0x08 0x151>;
			interrupts = <0x00 0x11 0x04 0x00>;
			gpio-controller;
			#gpio-cells = <0x02>;
			interrupt-controller;
			#interrupt-cells = <0x02>;
			phandle = <0x1f>;
		};

		gpio4@ff790000 {
			compatible = "rockchip,gpio-bank";
			reg = <0x00 0xff790000 0x00 0x100>;
			clocks = <0x08 0x152>;
			interrupts = <0x00 0x12 0x04 0x00>;
			gpio-controller;
			#gpio-cells = <0x02>;
			interrupt-controller;
			#interrupt-cells = <0x02>;
			phandle = <0xcb>;
		};

		pcfg-pull-up {
			bias-pull-up;
			phandle = <0xbf>;
		};

		pcfg-pull-down {
			bias-pull-down;
			phandle = <0xc0>;
		};

		pcfg-pull-none {
			bias-disable;
			phandle = <0xbc>;
		};

		pcfg-pull-none-10ma {
			bias-disable;
			drive-strength = <0x0a>;
		};

		pcfg-pull-none-12ma {
			bias-disable;
			drive-strength = <0x0c>;
			phandle = <0xbe>;
		};

		pcfg-pull-none-13ma {
			bias-disable;
			drive-strength = <0x0d>;
			phandle = <0xbd>;
		};

		pcfg-pull-none-18ma {
			bias-disable;
			drive-strength = <0x12>;
		};

		pcfg-pull-none-20ma {
			bias-disable;
			drive-strength = <0x14>;
		};

		pcfg-pull-up-2ma {
			bias-pull-up;
			drive-strength = <0x02>;
		};

		pcfg-pull-up-8ma {
			bias-pull-up;
			drive-strength = <0x08>;
		};

		pcfg-pull-up-10ma {
			bias-pull-up;
			drive-strength = <0x0a>;
		};

		pcfg-pull-up-18ma {
			bias-pull-up;
			drive-strength = <0x12>;
		};

		pcfg-pull-up-20ma {
			bias-pull-up;
			drive-strength = <0x14>;
		};

		pcfg-pull-down-4ma {
			bias-pull-down;
			drive-strength = <0x04>;
		};

		pcfg-pull-down-8ma {
			bias-pull-down;
			drive-strength = <0x08>;
		};

		pcfg-pull-down-12ma {
			bias-pull-down;
			drive-strength = <0x0c>;
		};

		pcfg-pull-down-18ma {
			bias-pull-down;
			drive-strength = <0x12>;
		};

		pcfg-pull-down-20ma {
			bias-pull-down;
			drive-strength = <0x14>;
		};

		pcfg-output-high {
			output-high;
		};

		pcfg-output-low {
			output-low;
		};

		clock {

			clk-32k {
				rockchip,pins = <0x00 0x00 0x02 0xbc>;
			};
		};

		edp {

			edp-hpd {
				rockchip,pins = <0x04 0x17 0x02 0xbc>;
				phandle = <0xb7>;
			};
		};

		gmac {

			rgmii-pins {
				rockchip,pins = <0x03 0x11 0x01 0xbd 0x03 0x0e 0x01 0xbc 0x03 0x0d 0x01 0xbc 0x03 0x0c 0x01 0xbd 0x03 0x0b 0x01 0xbc 0x03 0x09 0x01 0xbc 0x03 0x08 0x01 0xbc 0x03 0x07 0x01 0xbc 0x03 0x06 0x01 0xbc 0x03 0x05 0x01 0xbd 0x03 0x04 0x01 0xbd 0x03 0x03 0x01 0xbc 0x03 0x02 0x01 0xbc 0x03 0x01 0x01 0xbd 0x03 0x00 0x01 0xbd>;
				phandle = <0x1e>;
			};

			rmii-pins {
				rockchip,pins = <0x03 0x0d 0x01 0xbc 0x03 0x0c 0x01 0xbd 0x03 0x0b 0x01 0xbc 0x03 0x0a 0x01 0xbc 0x03 0x09 0x01 0xbc 0x03 0x08 0x01 0xbc 0x03 0x07 0x01 0xbc 0x03 0x06 0x01 0xbc 0x03 0x05 0x01 0xbd 0x03 0x04 0x01 0xbd>;
			};
		};

		i2c0 {

			i2c0-xfer {
				rockchip,pins = <0x01 0x0f 0x02 0xbc 0x01 0x10 0x02 0xbc>;
				phandle = <0x7b>;
			};
		};

		i2c1 {

			i2c1-xfer {
				rockchip,pins = <0x04 0x02 0x01 0xbc 0x04 0x01 0x01 0xbc>;
				phandle = <0x34>;
			};
		};

		i2c2 {

			i2c2-xfer {
				rockchip,pins = <0x02 0x01 0x02 0xbe 0x02 0x00 0x02 0xbe>;
				phandle = <0x35>;
			};
		};

		i2c3 {

			i2c3-xfer {
				rockchip,pins = <0x04 0x11 0x01 0xbc 0x04 0x10 0x01 0xbc>;
				phandle = <0x36>;
			};

			i2c3_gpio {
				rockchip,pins = <0x04 0x11 0x00 0xbc 0x04 0x10 0x00 0xbc>;
			};
		};

		i2c4 {

			i2c4-xfer {
				rockchip,pins = <0x01 0x0c 0x01 0xbc 0x01 0x0b 0x01 0xbc>;
				phandle = <0x81>;
			};
		};

		i2c5 {

			i2c5-xfer {
				rockchip,pins = <0x03 0x0b 0x02 0xbc 0x03 0x0a 0x02 0xbc>;
				phandle = <0x37>;
			};
		};

		i2c6 {

			i2c6-xfer {
				rockchip,pins = <0x02 0x0a 0x02 0xbc 0x02 0x09 0x02 0xbc>;
				phandle = <0x38>;
			};
		};

		i2c7 {

			i2c7-xfer {
				rockchip,pins = <0x02 0x08 0x02 0xbc 0x02 0x07 0x02 0xbc>;
				phandle = <0x39>;
			};
		};

		i2c8 {

			i2c8-xfer {
				rockchip,pins = <0x01 0x15 0x01 0xbc 0x01 0x14 0x01 0xbc>;
				phandle = <0x88>;
			};
		};

		i2s0 {

			i2s0-2ch-bus {
				rockchip,pins = <0x03 0x18 0x01 0xbc 0x03 0x19 0x01 0xbc 0x03 0x1a 0x01 0xbc 0x03 0x1b 0x01 0xbc 0x03 0x1f 0x01 0xbc 0x04 0x00 0x01 0xbc>;
			};

			i2s0-8ch-bus {
				rockchip,pins = <0x03 0x18 0x01 0xbc 0x03 0x19 0x01 0xbc 0x03 0x1a 0x01 0xbc 0x03 0x1b 0x01 0xbc 0x03 0x1c 0x01 0xbc 0x03 0x1d 0x01 0xbc 0x03 0x1e 0x01 0xbc 0x03 0x1f 0x01 0xbc>;
				phandle = <0x9b>;
			};

			i2s-8ch-mclk {
				rockchip,pins = <0x04 0x00 0x01 0xbc>;
			};
		};

		i2s1 {

			i2s1-2ch-bus {
				rockchip,pins = <0x04 0x03 0x01 0xbc 0x04 0x04 0x01 0xbc 0x04 0x05 0x01 0xbc 0x04 0x06 0x01 0xbc 0x04 0x07 0x01 0xbc>;
				phandle = <0x9c>;
			};
		};

		sdio0 {

			sdio0-bus1 {
				rockchip,pins = <0x02 0x14 0x01 0xbf>;
			};

			sdio0-bus4 {
				rockchip,pins = <0x02 0x14 0x01 0xbf 0x02 0x15 0x01 0xbf 0x02 0x16 0x01 0xbf 0x02 0x17 0x01 0xbf>;
			};

			sdio0-cmd {
				rockchip,pins = <0x02 0x18 0x01 0xbf>;
			};

			sdio0-clk {
				rockchip,pins = <0x02 0x19 0x01 0xbc>;
			};

			sdio0-cd {
				rockchip,pins = <0x02 0x1a 0x01 0xbf>;
			};

			sdio0-pwr {
				rockchip,pins = <0x02 0x1b 0x01 0xbf>;
			};

			sdio0-bkpwr {
				rockchip,pins = <0x02 0x1c 0x01 0xbf>;
			};

			sdio0-wp {
				rockchip,pins = <0x00 0x03 0x01 0xbf>;
			};

			sdio0-int {
				rockchip,pins = <0x00 0x04 0x01 0xbf>;
			};
		};

		sdmmc {

			sdmmc-bus1 {
				rockchip,pins = <0x04 0x08 0x01 0xbf>;
			};

			sdmmc-bus4 {
				rockchip,pins = <0x04 0x08 0x01 0xbf 0x04 0x09 0x01 0xbf 0x04 0x0a 0x01 0xbf 0x04 0x0b 0x01 0xbf>;
				phandle = <0x23>;
			};

			sdmmc-clk {
				rockchip,pins = <0x04 0x0c 0x01 0xbc>;
				phandle = <0x20>;
			};

			sdmmc-cmd {
				rockchip,pins = <0x04 0x0d 0x01 0xbf>;
				phandle = <0x21>;
			};

			sdmmc-cd {
				rockchip,pins = <0x00 0x07 0x01 0xbf>;
				phandle = <0x22>;
			};

			sdmmc-wp {
				rockchip,pins = <0x00 0x08 0x01 0xbf>;
			};
		};

		suspend {

			ap-pwroff {
				rockchip,pins = <0x01 0x05 0x01 0xbc>;
			};

			ddrio-pwroff {
				rockchip,pins = <0x00 0x01 0x01 0xbc>;
			};
		};

		spdif {

			spdif-bus {
				rockchip,pins = <0x04 0x15 0x01 0xbc>;
				phandle = <0x9a>;
			};

			spdif-bus-1 {
				rockchip,pins = <0x03 0x10 0x03 0xbc>;
			};
		};

		spi0 {

			spi0-clk {
				rockchip,pins = <0x03 0x06 0x02 0xbf>;
				phandle = <0x40>;
			};

			spi0-cs0 {
				rockchip,pins = <0x03 0x07 0x02 0xbf>;
				phandle = <0x43>;
			};

			spi0-cs1 {
				rockchip,pins = <0x03 0x08 0x02 0xbf>;
			};

			spi0-tx {
				rockchip,pins = <0x03 0x05 0x02 0xbf>;
				phandle = <0x41>;
			};

			spi0-rx {
				rockchip,pins = <0x03 0x04 0x02 0xbf>;
				phandle = <0x42>;
			};
		};

		spi1 {

			spi1-clk {
				rockchip,pins = <0x01 0x09 0x02 0xbf>;
				phandle = <0x44>;
			};

			spi1-cs0 {
				rockchip,pins = <0x01 0x0a 0x02 0xbf>;
				phandle = <0x47>;
			};

			spi1-rx {
				rockchip,pins = <0x01 0x07 0x02 0xbf>;
				phandle = <0x46>;
			};

			spi1-tx {
				rockchip,pins = <0x01 0x08 0x02 0xbf>;
				phandle = <0x45>;
			};
		};

		spi2 {

			spi2-clk {
				rockchip,pins = <0x02 0x0b 0x01 0xbf>;
				phandle = <0x48>;
			};

			spi2-cs0 {
				rockchip,pins = <0x02 0x0c 0x01 0xbf>;
				phandle = <0x4b>;
			};

			spi2-rx {
				rockchip,pins = <0x02 0x09 0x01 0xbf>;
				phandle = <0x4a>;
			};

			spi2-tx {
				rockchip,pins = <0x02 0x0a 0x01 0xbf>;
				phandle = <0x49>;
			};
		};

		spi3 {

			spi3-clk {
				rockchip,pins = <0x01 0x11 0x01 0xbf>;
				phandle = <0x76>;
			};

			spi3-cs0 {
				rockchip,pins = <0x01 0x12 0x01 0xbf>;
				phandle = <0x79>;
			};

			spi3-rx {
				rockchip,pins = <0x01 0x0f 0x01 0xbf>;
				phandle = <0x78>;
			};

			spi3-tx {
				rockchip,pins = <0x01 0x10 0x01 0xbf>;
				phandle = <0x77>;
			};
		};

		spi4 {

			spi4-clk {
				rockchip,pins = <0x03 0x02 0x02 0xbf>;
				phandle = <0x4c>;
			};

			spi4-cs0 {
				rockchip,pins = <0x03 0x03 0x02 0xbf>;
				phandle = <0x4f>;
			};

			spi4-rx {
				rockchip,pins = <0x03 0x00 0x02 0xbf>;
				phandle = <0x4e>;
			};

			spi4-tx {
				rockchip,pins = <0x03 0x01 0x02 0xbf>;
				phandle = <0x4d>;
			};
		};

		spi5 {

			spi5-clk {
				rockchip,pins = <0x02 0x16 0x02 0xbf>;
				phandle = <0x51>;
			};

			spi5-cs0 {
				rockchip,pins = <0x02 0x17 0x02 0xbf>;
				phandle = <0x54>;
			};

			spi5-rx {
				rockchip,pins = <0x02 0x14 0x02 0xbf>;
				phandle = <0x53>;
			};

			spi5-tx {
				rockchip,pins = <0x02 0x15 0x02 0xbf>;
				phandle = <0x52>;
			};
		};

		testclk {

			test-clkout0 {
				rockchip,pins = <0x00 0x00 0x01 0xbc>;
			};

			test-clkout1 {
				rockchip,pins = <0x02 0x19 0x02 0xbc>;
			};

			test-clkout2 {
				rockchip,pins = <0x00 0x08 0x03 0xbc>;
			};
		};

		tsadc {

			otp-pin {
				rockchip,pins = <0x01 0x06 0x00 0xbc>;
				phandle = <0x59>;
			};

			otp-out {
				rockchip,pins = <0x01 0x06 0x01 0xbc>;
				phandle = <0x5a>;
			};
		};

		uart0 {

			uart0-xfer {
				rockchip,pins = <0x02 0x10 0x01 0xbf 0x02 0x11 0x01 0xbf>;
				phandle = <0x3a>;
			};

			uart0-cts {
				rockchip,pins = <0x02 0x12 0x01 0xbc>;
				phandle = <0x3b>;
			};

			uart0-rts {
				rockchip,pins = <0x02 0x13 0x01 0xbc>;
			};
		};

		uart1 {

			uart1-xfer {
				rockchip,pins = <0x03 0x0c 0x02 0xbf 0x03 0x0d 0x02 0xbf>;
				phandle = <0x3c>;
			};
		};

		uart2a {

			uart2a-xfer {
				rockchip,pins = <0x04 0x08 0x02 0xbf 0x04 0x09 0x02 0xbf>;
			};
		};

		uart2b {

			uart2b-xfer {
				rockchip,pins = <0x04 0x10 0x02 0xbf 0x04 0x11 0x02 0xbf>;
			};
		};

		uart2c {

			uart2c-xfer {
				rockchip,pins = <0x04 0x13 0x01 0xbf 0x04 0x14 0x01 0xbf>;
				phandle = <0x3d>;
			};
		};

		uart3 {

			uart3-xfer {
				rockchip,pins = <0x03 0x0e 0x02 0xbf 0x03 0x0f 0x02 0xbf>;
				phandle = <0x3e>;
			};

			uart3-cts {
				rockchip,pins = <0x03 0x10 0x02 0xbc>;
			};

			uart3-rts {
				rockchip,pins = <0x03 0x11 0x02 0xbc>;
			};
		};

		uart4 {

			uart4-xfer {
				rockchip,pins = <0x01 0x07 0x01 0xbf 0x01 0x08 0x01 0xbf>;
				phandle = <0x7a>;
			};
		};

		uarthdcp {

			uarthdcp-xfer {
				rockchip,pins = <0x04 0x15 0x02 0xbf 0x04 0x16 0x02 0xbf>;
			};
		};

		pwm0 {

			pwm0-pin {
				rockchip,pins = <0x04 0x12 0x01 0xbc>;
				phandle = <0x89>;
			};

			pwm0-pin-pull-down {
				rockchip,pins = <0x04 0x12 0x01 0xc0>;
			};

			vop0-pwm-pin {
				rockchip,pins = <0x04 0x12 0x02 0xbc>;
				phandle = <0xaa>;
			};

			vop1-pwm-pin {
				rockchip,pins = <0x04 0x12 0x03 0xbc>;
				phandle = <0xa3>;
			};
		};

		pwm1 {

			pwm1-pin {
				rockchip,pins = <0x04 0x16 0x01 0xbc>;
				phandle = <0x8a>;
			};

			pwm1-pin-pull-down {
				rockchip,pins = <0x04 0x16 0x01 0xc0>;
			};
		};

		pwm2 {

			pwm2-pin {
				rockchip,pins = <0x01 0x13 0x01 0xbc>;
			};

			pwm2-pin-pull-down {
				rockchip,pins = <0x01 0x13 0x01 0xc0>;
				phandle = <0x8b>;
			};
		};

		pwm3a {

			pwm3a-pin {
				rockchip,pins = <0x00 0x06 0x01 0xbc>;
				phandle = <0x8c>;
			};

			pwm3a-pin-pull-down {
				rockchip,pins = <0x00 0x06 0x01 0xc0>;
			};
		};

		pwm3b {

			pwm3b-pin {
				rockchip,pins = <0x01 0x0e 0x01 0xbc>;
			};

			pwm3b-pin-pull-down {
				rockchip,pins = <0x01 0x0e 0x01 0xc0>;
			};
		};

		hdmi {

			hdmi-i2c-xfer {
				rockchip,pins = <0x04 0x11 0x03 0xbc 0x04 0x10 0x03 0xbc>;
				phandle = <0xb0>;
			};

			hdmi-cec {
				rockchip,pins = <0x04 0x17 0x01 0xbc>;
			};
		};

		pcie {

			pci-clkreqn-cpm {
				rockchip,pins = <0x02 0x1a 0x00 0xbc>;
			};

			pci-clkreqnb-cpm {
				rockchip,pins = <0x04 0x18 0x00 0xbc>;
			};
		};

		buttons {

			pwr-btn {
				rockchip,pins = <0x00 0x05 0x00 0xbf>;
				phandle = <0xc8>;
			};
		};

		fan {

			motor-pwr {
				rockchip,pins = <0x01 0x12 0x00 0xbc>;
			};
		};

		pmic {

			pmic-int-l {
				rockchip,pins = <0x01 0x15 0x00 0xbf>;
				phandle = <0x7d>;
			};

			vsel1-pin {
				rockchip,pins = <0x01 0x11 0x00 0xc0>;
			};

			vsel2-pin {
				rockchip,pins = <0x01 0x0e 0x00 0xc0>;
			};
		};

		sd {

			sdmmc0-pwr-h {
				rockchip,pins = <0x00 0x01 0x00 0xbc>;
				phandle = <0xca>;
			};
		};

		usb2 {

			vcc5v0-host-en {
				rockchip,pins = <0x04 0x19 0x00 0xbc>;
				phandle = <0xcc>;
			};
		};

		usb-typec {

			usbc0-int {
				rockchip,pins = <0x01 0x02 0x00 0xbf>;
				phandle = <0x82>;
			};

			vcc5v0-typec0-en {
				rockchip,pins = <0x02 0x00 0x00 0xbc>;
				phandle = <0xce>;
			};
		};
	};

	rockchip-suspend {
		compatible = "rockchip,pm-rk3399";
		status = "disabled";
		rockchip,sleep-debug-en = <0x00>;
		rockchip,virtual-poweroff = <0x00>;
		rockchip,sleep-mode-config = <0xfe>;
		rockchip,wakeup-config = <0x04>;
	};

	energy-costs {

		rk3399-core-cost0 {
			busy-cost-data = <0x6c 0x2e 0x9f 0x43 0xd8 0x5a 0x10b 0x78 0x13e 0x99 0x177 0xc6 0x191 0xde>;
			idle-cost-data = <0x06 0x06 0x00 0x00>;
			phandle = <0x0c>;
		};

		rk3399-core-cost1 {
			busy-cost-data = <0xd2 0x81 0x134 0xb8 0x1a3 0xf6 0x206 0x14f 0x269 0x1ac 0x2d8 0x23d 0x33b 0x2d4 0x39d 0x384 0x400 0x454>;
			idle-cost-data = <0x0f 0x0f 0x00 0x00>;
			phandle = <0x10>;
		};

		rk3399-cluster-cost0 {
			busy-cost-data = <0x6c 0x2e 0x9f 0x43 0xd8 0x5a 0x10b 0x78 0x13e 0x99 0x177 0xc6 0x191 0xde>;
			idle-cost-data = <0x38 0x38 0x38 0x38>;
			phandle = <0x0d>;
		};

		rk3399-cluster-cost1 {
			busy-cost-data = <0xd2 0x81 0x134 0xb8 0x1a3 0xf6 0x206 0x14f 0x269 0x1ac 0x2d8 0x23d 0x33b 0x2d4 0x39d 0x384 0x400 0x454>;
			idle-cost-data = <0x41 0x41 0x41 0x41>;
			phandle = <0x11>;
		};
	};

	opp-table0 {
		compatible = "operating-points-v2";
		opp-shared;
		rockchip,temp-hysteresis = <0x1388>;
		rockchip,low-temp = <0x2710>;
		rockchip,low-temp-min-volt = <0xdbba0>;
		nvmem-cells = <0xc1 0xc2 0xc3>;
		nvmem-cell-names = "cpu_leakage\0specification_serial_number\0customer_demand";
		clocks = <0x08 0x01>;
		rockchip,avs-scale = <0x14>;
		rockchip,bin-scaling-sel = <0x00 0x1e 0x01 0x22>;
		rockchip,pvtm-voltage-sel = <0x00 0x2308c 0x00 0x2308d 0x24414 0x01 0x24415 0x251c0 0x02 0x251c1 0xf423f 0x03>;
		rockchip,pvtm-freq = <0x639c0>;
		rockchip,pvtm-volt = <0xf4240>;
		rockchip,pvtm-ch = <0x00 0x00>;
		rockchip,pvtm-sample-time = <0x3e8>;
		rockchip,pvtm-number = <0x0a>;
		rockchip,pvtm-error = <0x3e8>;
		rockchip,pvtm-ref-temp = <0x29>;
		rockchip,pvtm-temp-prop = <0x73 0x42>;
		rockchip,pvtm-thermal-zone = "soc-thermal";
		phandle = <0x0b>;

		opp-408000000 {
			opp-hz = <0x00 0x18519600>;
			opp-microvolt = <0xc96a8 0xc96a8 0x1312d0>;
			opp-microvolt-L0 = <0xc96a8 0xc96a8 0x1312d0>;
			opp-microvolt-L1 = <0xc96a8 0xc96a8 0x1312d0>;
			opp-microvolt-L2 = <0xc96a8 0xc96a8 0x1312d0>;
			opp-microvolt-L3 = <0xc96a8 0xc96a8 0x1312d0>;
			clock-latency-ns = <0x9c40>;
		};

		opp-600000000 {
			opp-hz = <0x00 0x23c34600>;
			opp-microvolt = <0xc96a8 0xc96a8 0x1312d0>;
			opp-microvolt-L0 = <0xc96a8 0xc96a8 0x1312d0>;
			opp-microvolt-L1 = <0xc96a8 0xc96a8 0x1312d0>;
			opp-microvolt-L2 = <0xc96a8 0xc96a8 0x1312d0>;
			opp-microvolt-L3 = <0xc96a8 0xc96a8 0x1312d0>;
			clock-latency-ns = <0x9c40>;
		};

		opp-816000000 {
			opp-hz = <0x00 0x30a32c00>;
			opp-microvolt = <0xcf850 0xcf850 0x1312d0>;
			opp-microvolt-L0 = <0xcf850 0xcf850 0x1312d0>;
			opp-microvolt-L1 = <0xc96a8 0xc96a8 0x1312d0>;
			opp-microvolt-L2 = <0xc96a8 0xc96a8 0x1312d0>;
			opp-microvolt-L3 = <0xc96a8 0xc96a8 0x1312d0>;
			clock-latency-ns = <0x9c40>;
			opp-suspend;
		};

		opp-1008000000 {
			opp-hz = <0x00 0x3c14dc00>;
			opp-microvolt = <0xe1d48 0xe1d48 0x1312d0>;
			opp-microvolt-L0 = <0xe1d48 0xe1d48 0x1312d0>;
			opp-microvolt-L1 = <0xdbba0 0xdbba0 0x1312d0>;
			opp-microvolt-L2 = <0xd59f8 0xd59f8 0x1312d0>;
			opp-microvolt-L3 = <0xcf850 0xcf850 0x1312d0>;
			clock-latency-ns = <0x9c40>;
		};

		opp-1200000000 {
			opp-hz = <0x00 0x47868c00>;
			opp-microvolt = <0xf4240 0xf4240 0x1312d0>;
			opp-microvolt-L0 = <0xf4240 0xf4240 0x1312d0>;
			opp-microvolt-L1 = <0xee098 0xee098 0x1312d0>;
			opp-microvolt-L2 = <0xe7ef0 0xe7ef0 0x1312d0>;
			opp-microvolt-L3 = <0xe1d48 0xe1d48 0x1312d0>;
			clock-latency-ns = <0x9c40>;
		};

		opp-1416000000 {
			opp-hz = <0x00 0x54667200>;
			opp-microvolt = <0x112a88 0x112a88 0x1312d0>;
			opp-microvolt-L0 = <0x112a88 0x112a88 0x1312d0>;
			opp-microvolt-L1 = <0x10c8e0 0x10c8e0 0x1312d0>;
			opp-microvolt-L2 = <0x106738 0x106738 0x124f80>;
			opp-microvolt-L3 = <0x100590 0x100590 0x1312d0>;
			clock-latency-ns = <0x9c40>;
		};
	};

	opp-table1 {
		compatible = "operating-points-v2";
		opp-shared;
		rockchip,temp-hysteresis = <0x1388>;
		rockchip,low-temp = <0x2710>;
		rockchip,low-temp-min-volt = <0xdbba0>;
		nvmem-cells = <0xc4 0xc2 0xc3>;
		nvmem-cell-names = "cpu_leakage\0specification_serial_number\0customer_demand";
		clocks = <0x08 0x02>;
		rockchip,avs-scale = <0x08>;
		rockchip,bin-scaling-sel = <0x00 0x08 0x01 0x11>;
		rockchip,pvtm-voltage-sel = <0x00 0x24608 0x00 0x24609 0x25d78 0x01 0x25d79 0x26d18 0x02 0x26d19 0x274e8 0x03 0x274e9 0xf423f 0x04>;
		rockchip,pvtm-freq = <0x639c0>;
		rockchip,pvtm-volt = <0xf4240>;
		rockchip,pvtm-ch = <0x01 0x00>;
		rockchip,pvtm-sample-time = <0x3e8>;
		rockchip,pvtm-number = <0x0a>;
		rockchip,pvtm-error = <0x3e8>;
		rockchip,pvtm-ref-temp = <0x29>;
		rockchip,pvtm-temp-prop = <0x47 0x23>;
		rockchip,pvtm-thermal-zone = "soc-thermal";
		phandle = <0x0f>;

		opp-408000000 {
			opp-hz = <0x00 0x18519600>;
			opp-microvolt = <0xc96a8 0xc96a8 0x1312d0>;
			opp-microvolt-L0 = <0xc96a8 0xc96a8 0x1312d0>;
			opp-microvolt-L1 = <0xc96a8 0xc96a8 0x1312d0>;
			opp-microvolt-L2 = <0xc96a8 0xc96a8 0x1312d0>;
			opp-microvolt-L3 = <0xc96a8 0xc96a8 0x1312d0>;
			opp-microvolt-L4 = <0xc96a8 0xc96a8 0x1312d0>;
			clock-latency-ns = <0x9c40>;
		};

		opp-600000000 {
			opp-hz = <0x00 0x23c34600>;
			opp-microvolt = <0xc96a8 0xc96a8 0x1312d0>;
			opp-microvolt-L0 = <0xc96a8 0xc96a8 0x1312d0>;
			opp-microvolt-L1 = <0xc96a8 0xc96a8 0x1312d0>;
			opp-microvolt-L2 = <0xc96a8 0xc96a8 0x1312d0>;
			opp-microvolt-L3 = <0xc96a8 0xc96a8 0x1312d0>;
			opp-microvolt-L4 = <0xc96a8 0xc96a8 0x1312d0>;
			clock-latency-ns = <0x9c40>;
		};

		opp-816000000 {
			opp-hz = <0x00 0x30a32c00>;
			opp-microvolt = <0xc96a8 0xc96a8 0x1312d0>;
			opp-microvolt-L0 = <0xc96a8 0xc96a8 0x1312d0>;
			opp-microvolt-L1 = <0xc96a8 0xc96a8 0x1312d0>;
			opp-microvolt-L2 = <0xc96a8 0xc96a8 0x1312d0>;
			opp-microvolt-L3 = <0xc96a8 0xc96a8 0x1312d0>;
			opp-microvolt-L4 = <0xc96a8 0xc96a8 0x1312d0>;
			clock-latency-ns = <0x9c40>;
			opp-suspend;
		};

		opp-1008000000 {
			opp-hz = <0x00 0x3c14dc00>;
			opp-microvolt = <0xd59f8 0xd59f8 0x1312d0>;
			opp-microvolt-L0 = <0xd59f8 0xd59f8 0x1312d0>;
			opp-microvolt-L1 = <0xcf850 0xcf850 0x1312d0>;
			opp-microvolt-L2 = <0xcf850 0xcf850 0x1312d0>;
			opp-microvolt-L3 = <0xcf850 0xcf850 0x1312d0>;
			opp-microvolt-L4 = <0xcf850 0xcf850 0x1312d0>;
			clock-latency-ns = <0x9c40>;
		};

		opp-1200000000 {
			opp-hz = <0x00 0x47868c00>;
			opp-microvolt = <0xe7ef0 0xe7ef0 0x1312d0>;
			opp-microvolt-L0 = <0xe7ef0 0xe7ef0 0x1312d0>;
			opp-microvolt-L1 = <0xe1d48 0xe1d48 0x1312d0>;
			opp-microvolt-L2 = <0xdbba0 0xdbba0 0x1312d0>;
			opp-microvolt-L3 = <0xd59f8 0xd59f8 0x1312d0>;
			opp-microvolt-L4 = <0xd59f8 0xd59f8 0x1312d0>;
			clock-latency-ns = <0x9c40>;
		};

		opp-1416000000 {
			opp-hz = <0x00 0x54667200>;
			opp-microvolt = <0xfa3e8 0xfa3e8 0x1312d0>;
			opp-microvolt-L0 = <0xfa3e8 0xfa3e8 0x1312d0>;
			opp-microvolt-L1 = <0xf4240 0xf4240 0x1312d0>;
			opp-microvolt-L2 = <0xf4240 0xf4240 0x1312d0>;
			opp-microvolt-L3 = <0xee098 0xee098 0x1312d0>;
			opp-microvolt-L4 = <0xee098 0xee098 0x1312d0>;
			clock-latency-ns = <0x9c40>;
		};

		opp-1608000000 {
			opp-hz = <0x00 0x5fd82200>;
			opp-microvolt = <0x10c8e0 0x10c8e0 0x1312d0>;
			opp-microvolt-L0 = <0x10c8e0 0x10c8e0 0x1312d0>;
			opp-microvolt-L1 = <0x106738 0x106738 0x1312d0>;
			opp-microvolt-L2 = <0x100590 0x100590 0x1312d0>;
			opp-microvolt-L3 = <0xfa3e8 0xfa3e8 0x1312d0>;
			opp-microvolt-L4 = <0xfa3e8 0xfa3e8 0x1312d0>;
			clock-latency-ns = <0x9c40>;
		};

		opp-1800000000 {
			opp-hz = <0x00 0x6b49d200>;
			opp-microvolt = <0x124f80 0x124f80 0x1312d0>;
			opp-microvolt-L0 = <0x124f80 0x124f80 0x1312d0>;
			opp-microvolt-L1 = <0x11edd8 0x11edd8 0x1312d0>;
			opp-microvolt-L2 = <0x118c30 0x118c30 0x1312d0>;
			opp-microvolt-L3 = <0x112a88 0x112a88 0x1312d0>;
			opp-microvolt-L4 = <0x10c8e0 0x10c8e0 0x1312d0>;
			clock-latency-ns = <0x9c40>;
		};
	};

	opp-table2 {
		compatible = "operating-points-v2";
		rockchip,thermal-zone = "soc-thermal";
		rockchip,temp-hysteresis = <0x1388>;
		rockchip,low-temp = <0x2710>;
		rockchip,low-temp-min-volt = <0xdbba0>;
		nvmem-cells = <0xc5>;
		nvmem-cell-names = "gpu_leakage";
		rockchip,pvtm-voltage-sel = <0x00 0x1d8a8 0x00 0x1d8a9 0x1ea3c 0x01 0x1ea3d 0x1f5f4 0x02 0x1f5f5 0xf423f 0x03>;
		rockchip,pvtm-freq = <0x30d40>;
		rockchip,pvtm-volt = <0xdbba0>;
		rockchip,pvtm-ch = <0x03 0x00>;
		rockchip,pvtm-sample-time = <0x3e8>;
		rockchip,pvtm-number = <0x0a>;
		rockchip,pvtm-error = <0x3e8>;
		rockchip,pvtm-ref-temp = <0x29>;
		rockchip,pvtm-temp-prop = <0x2e 0x0c>;
		rockchip,pvtm-thermal-zone = "gpu-thermal";
		phandle = <0xba>;

		opp-200000000 {
			opp-hz = <0x00 0xbebc200>;
			opp-microvolt = <0xc96a8>;
			opp-microvolt-L0 = <0xc96a8>;
			opp-microvolt-L1 = <0xc96a8>;
			opp-microvolt-L2 = <0xc96a8>;
			opp-microvolt-L3 = <0xc96a8>;
		};

		opp-300000000 {
			opp-hz = <0x00 0x11e1a300>;
			opp-microvolt = <0xc96a8>;
			opp-microvolt-L0 = <0xc96a8>;
			opp-microvolt-L1 = <0xc96a8>;
			opp-microvolt-L2 = <0xc96a8>;
			opp-microvolt-L3 = <0xc96a8>;
		};

		opp-400000000 {
			opp-hz = <0x00 0x17d78400>;
			opp-microvolt = <0xc96a8>;
			opp-microvolt-L0 = <0xc96a8>;
			opp-microvolt-L1 = <0xc96a8>;
			opp-microvolt-L2 = <0xc96a8>;
			opp-microvolt-L3 = <0xc96a8>;
		};

		opp-600000000 {
			opp-hz = <0x00 0x23c34600>;
			opp-microvolt = <0xe1d48>;
			opp-microvolt-L0 = <0xe1d48>;
			opp-microvolt-L1 = <0xe1d48>;
			opp-microvolt-L2 = <0xdbba0>;
			opp-microvolt-L3 = <0xdbba0>;
		};

		opp-800000000 {
			opp-hz = <0x00 0x2faf0800>;
			opp-microvolt = <0x10c8e0>;
			opp-microvolt-L0 = <0x10c8e0>;
			opp-microvolt-L1 = <0x106738>;
			opp-microvolt-L2 = <0x100590>;
			opp-microvolt-L3 = <0xfa3e8>;
		};
	};

	opp-table3 {
		compatible = "operating-points-v2";
		phandle = <0x90>;

		opp-200000000 {
			opp-hz = <0x00 0xbebc200>;
			opp-microvolt = <0xdbba0>;
		};

		opp-300000000 {
			opp-hz = <0x00 0x11e1a300>;
			opp-microvolt = <0xdbba0>;
		};

		opp-400000000 {
			opp-hz = <0x00 0x17d78400>;
			opp-microvolt = <0xdbba0>;
		};

		opp-528000000 {
			opp-hz = <0x00 0x1f78a400>;
			opp-microvolt = <0xdbba0>;
		};

		opp-600000000 {
			opp-hz = <0x00 0x23c34600>;
			opp-microvolt = <0xdbba0>;
		};

		opp-800000000 {
			opp-hz = <0x00 0x2faf0800>;
			opp-microvolt = <0xdbba0>;
		};
	};

	chosen {
		stdout-path = "serial2:1500000n8";
	};

	adc-keys {
		compatible = "adc-keys";
		io-channels = <0xc6 0x01>;
		io-channel-names = "buttons";
		keyup-threshold-microvolt = <0x1b7740>;
		poll-interval = <0x64>;

		vol-up-key {
			label = "volume up";
			linux,code = <0x73>;
			press-threshold-microvolt = <0x6d6>;
		};

		vol-down-key {
			label = "volume down";
			linux,code = <0x72>;
			press-threshold-microvolt = <0x48a1c>;
		};

		menu-key {
			label = "menu";
			linux,code = <0x8b>;
			press-threshold-microvolt = <0x13eb9c>;
		};

		home-key {
			label = "home";
			linux,code = <0x66>;
			press-threshold-microvolt = <0x97ac2>;
		};

		back-key {
			label = "back";
			linux,code = <0x9e>;
			press-threshold-microvolt = <0xef420>;
		};

		camera-key {
			label = "camera";
			linux,code = <0xd4>;
			press-threshold-microvolt = <0xc042c>;
		};
	};

	external-gmac-clock {
		compatible = "fixed-clock";
		clock-frequency = <0x7735940>;
		clock-output-names = "clkin_gmac";
		#clock-cells = <0x00>;
		phandle = <0x1c>;
	};

	dc-12v {
		compatible = "regulator-fixed";
		regulator-name = "dc_12v";
		regulator-always-on;
		regulator-boot-on;
		regulator-min-microvolt = <0xb71b00>;
		regulator-max-microvolt = <0xb71b00>;
		phandle = <0xcf>;
	};

	gpio-fan {
		#cooling-cells = <0x02>;
		compatible = "gpio-fan";
		gpio-fan,speed-map = <0x00 0x00 0xbb8 0x01>;
		gpios = <0x7c 0x12 0x00>;
		status = "okay";
		phandle = <0x58>;
	};

	gpio-keys {
		compatible = "gpio-keys";
		autorepeat;

		power {
			debounce-interval = <0x64>;
			gpios = <0xc7 0x05 0x01>;
			label = "GPIO Power";
			linux,code = <0x74>;
			linux,input-type = <0x01>;
			pinctrl-names = "default";
			pinctrl-0 = <0xc8>;
			wakeup-source;
		};
	};

	vcc1v8-s3 {
		compatible = "regulator-fixed";
		regulator-name = "vcc1v8_s3";
		regulator-always-on;
		regulator-boot-on;
		regulator-min-microvolt = <0x1b7740>;
		regulator-max-microvolt = <0x1b7740>;
		vin-supply = <0xc9>;
		phandle = <0x33>;
	};

	vcc3v0-sd {
		compatible = "regulator-fixed";
		enable-active-high;
		gpio = <0xc7 0x01 0x00>;
		pinctrl-names = "default";
		pinctrl-0 = <0xca>;
		regulator-always-on;
		regulator-max-microvolt = <0x2dc6c0>;
		regulator-min-microvolt = <0x2dc6c0>;
		regulator-name = "vcc3v0_sd";
		vin-supply = <0x7f>;
		phandle = <0x24>;
	};

	vcc3v3-sys {
		compatible = "regulator-fixed";
		regulator-name = "vcc3v3_sys";
		regulator-always-on;
		regulator-boot-on;
		regulator-min-microvolt = <0x325aa0>;
		regulator-max-microvolt = <0x325aa0>;
		vin-supply = <0x7e>;
		phandle = <0x7f>;
	};

	vcc5v0-host-regulator {
		compatible = "regulator-fixed";
		enable-active-high;
		gpio = <0xcb 0x19 0x00>;
		pinctrl-names = "default";
		pinctrl-0 = <0xcc>;
		regulator-name = "vcc5v0_host";
		regulator-always-on;
		vin-supply = <0x7e>;
		phandle = <0x96>;
	};

	vcc5v0-typec0-regulator {
		compatible = "regulator-fixed";
		enable-active-high;
		gpio = <0xcd 0x00 0x00>;
		pinctrl-names = "default";
		pinctrl-0 = <0xce>;
		regulator-name = "vcc5v0_typec0";
		vin-supply = <0x7e>;
		phandle = <0x83>;
	};

	vcc-sys {
		compatible = "regulator-fixed";
		regulator-name = "vcc_sys";
		regulator-always-on;
		regulator-boot-on;
		regulator-min-microvolt = <0x4c4b40>;
		regulator-max-microvolt = <0x4c4b40>;
		vin-supply = <0xcf>;
		phandle = <0x7e>;
	};

	vdd-log {
		compatible = "pwm-regulator";
		pwms = <0xd0 0x00 0x61a8 0x01>;
		regulator-name = "vdd_log";
		regulator-always-on;
		regulator-boot-on;
		regulator-min-microvolt = "\0\f5";
		regulator-max-microvolt = <0x155cc0>;
		vin-supply = <0x7e>;
	};
};
